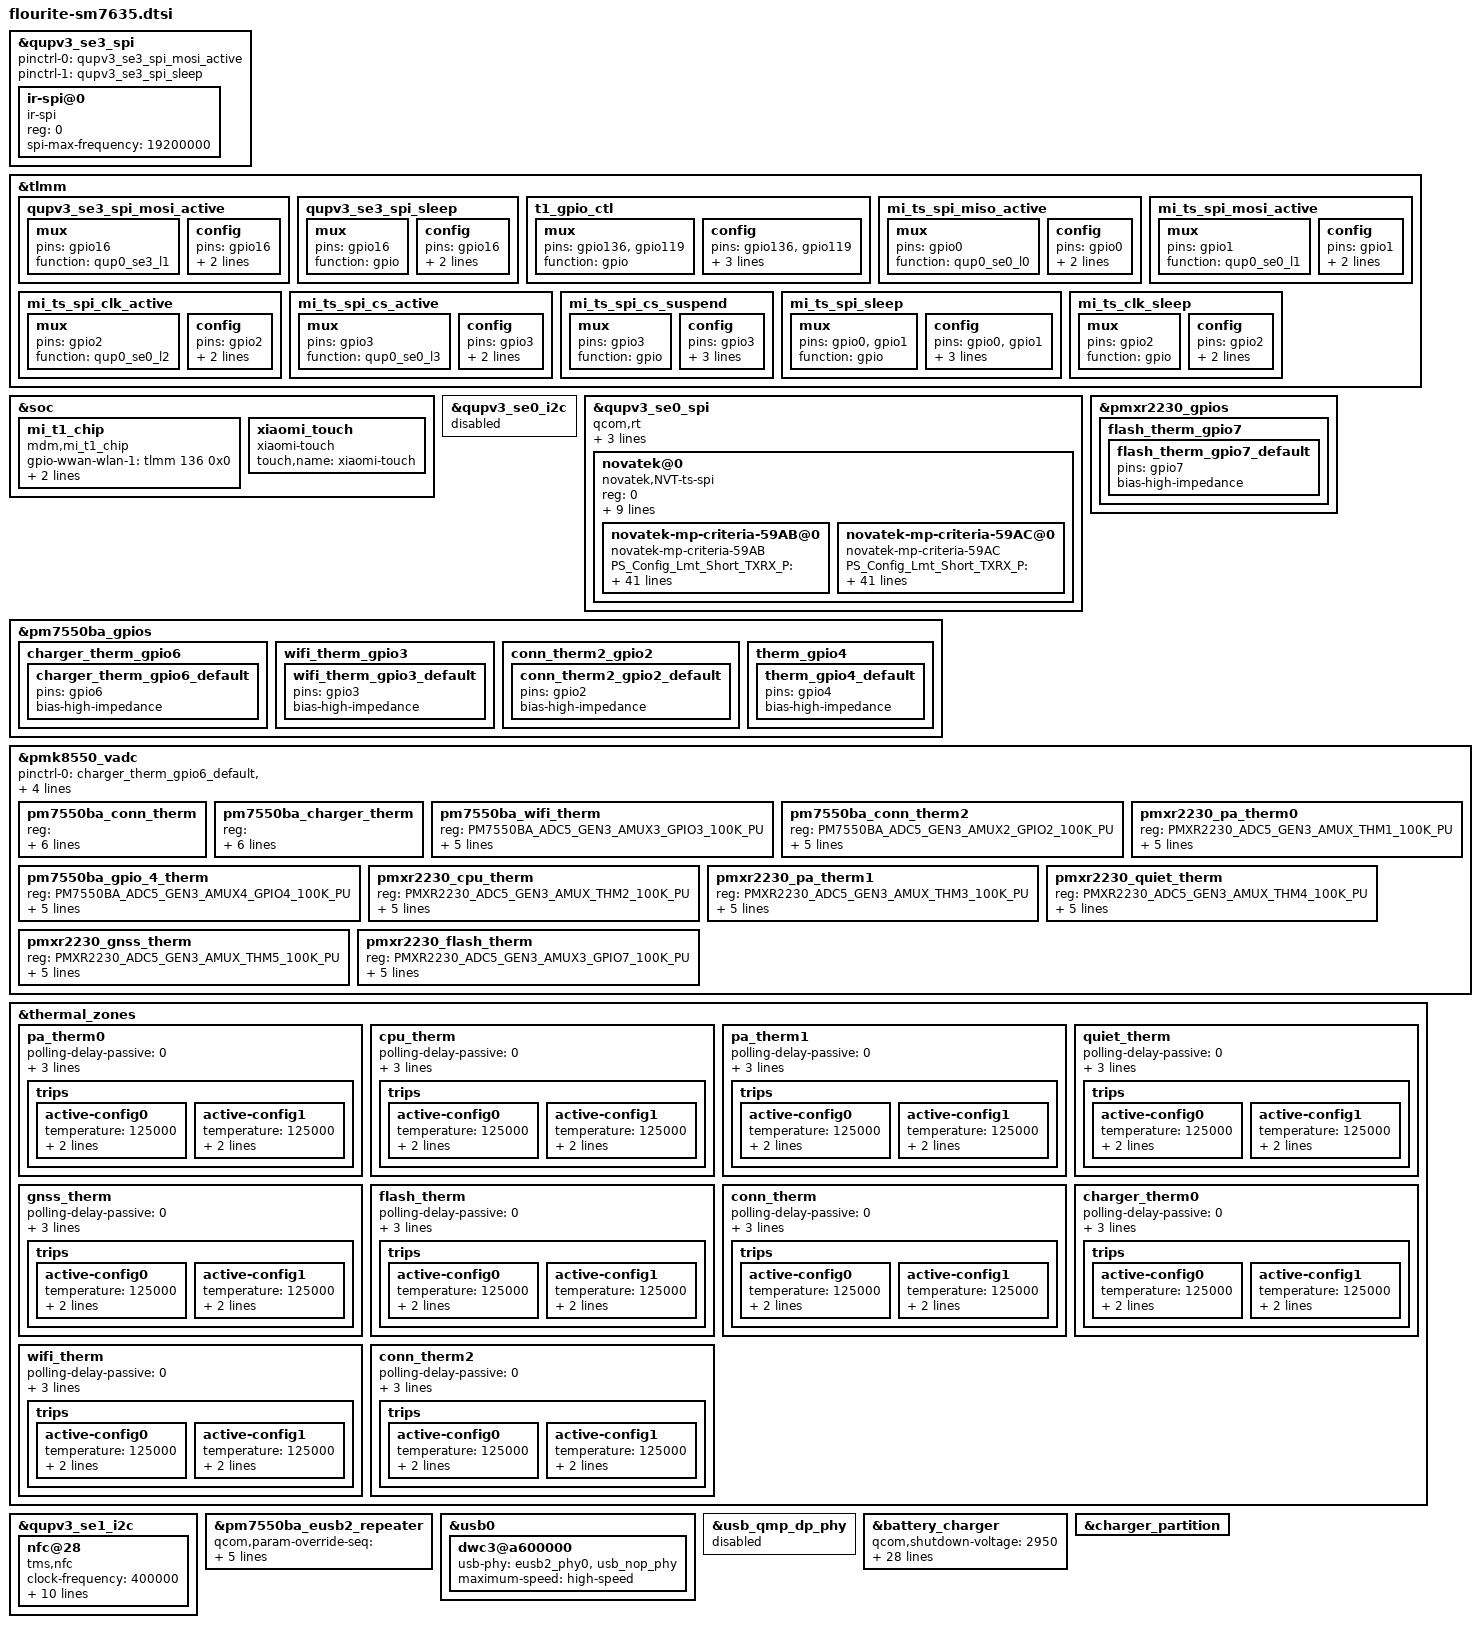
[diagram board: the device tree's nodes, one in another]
/*
  this file is for attribution only of flourite
  And public attribution of xiaomi platforms(like flourite and so and)
*/
#include "flourite-pinctrl.dtsi"
#include "xiaomi-sm7635-common.dtsi"
#include "volcano-pm7550ba.dtsi"
#include <dt-bindings/iio/qcom,spmi-adc5-gen3-pmxr2230.h>
#include "flourite-sm7635-xiaomi-fingerprint.dtsi"
#include "flourite-sm7635-xiaomi-hdbds.dtsi"

/* SENSOR start */
&qupv3_se3_spi {
	status = "ok";
	pinctrl-names = "default", "sleep";
	pinctrl-0 = <&qupv3_se3_spi_mosi_active>;
	pinctrl-1 = <&qupv3_se3_spi_sleep>;
	ir-spi@0 {
		compatible = "ir-spi";
		reg = <0>;
		spi-max-frequency = <19200000>;
		status = "ok";
	};
};

&tlmm {
	qupv3_se3_spi_mosi_active: qupv3_se3_spi_mosi_active {
		mux {
			pins = "gpio16";
			function = "qup0_se3_l1";
		};

		config {
			pins = "gpio16";
			drive-strength = <6>;
			bias-disable;
		};
	};

	qupv3_se3_spi_sleep: qupv3_se3_spi_sleep {
		mux {
			pins = "gpio16";
			function = "gpio";
		};

		config {
			pins = "gpio16";
			drive-strength = <2>;
			bias-disable;
		};
	};
};
/* SENSOR end */

/*modem start: t1 chip*/
&soc {
        mi_t1_chip {
                compatible = "mdm,mi_t1_chip";
                gpio-wwan-wlan-1 = <&tlmm 136 0x0>;
                gpio-wwan-wlan-2 = <&tlmm 119 0x0>;
                pinctrl-0       = <&t1_gpio_ctl>;
        };
};

&tlmm {
	t1_gpio_ctl: t1_gpio_ctl {
		mux {
			pins = "gpio136", "gpio119";
			function = "gpio";
		};
		config {
			pins = "gpio136", "gpio119";
			drive-strength = <2>;
			bias-disable;
			output-enable;
		};
	};
};
/*modem end: t1 chip*/


/*touch start*/
&soc {
	xiaomi_touch {
		compatible = "xiaomi-touch";
		status = "ok";
		touch,name = "xiaomi-touch";
	};
};

&qupv3_se0_i2c {
	status = "disable";
};

&tlmm {
	mi_ts_spi_miso_active: mi_ts_spi_miso_active {
		mux {
			pins = "gpio0";
			function = "qup0_se0_l0";
		};
		config {
			pins = "gpio0";
			drive-strength = <6>;
			bias-disable;
		};
	};
	mi_ts_spi_mosi_active: mi_ts_spi_mosi_active {
		mux {
			pins = "gpio1";
			function = "qup0_se0_l1";
		};
		config {
			pins = "gpio1";
			drive-strength = <6>;
			bias-disable;
		};
	};
	mi_ts_spi_clk_active: mi_ts_spi_clk_active {
		mux {
			pins = "gpio2";
			function = "qup0_se0_l2";
		};
		config {
			pins = "gpio2";
			drive-strength = <6>;
			bias-disable;
		};
	};
	mi_ts_spi_cs_active: mi_ts_spi_cs_active {
		mux {
			pins = "gpio3";
			function = "qup0_se0_l3";
		};
		config {
			pins = "gpio3";
			drive-strength = <6>;
			bias-disable;
		};
	};
	mi_ts_spi_cs_suspend: mi_ts_spi_cs_suspend {
		mux {
			pins = "gpio3";
			function = "gpio";
		};
		config {
			pins = "gpio3";
			drive-strength = <2>;
			bias-pull-down;
			output-low;
		};
	};
	mi_ts_spi_sleep: mi_ts_spi_sleep {
		mux {
			pins = "gpio0", "gpio1";
			function = "gpio";
		};
		config {
			pins = "gpio0", "gpio1";
			drive-strength = <2>;
			output-low;
			bias-disable;
		};
	};
	mi_ts_clk_sleep: mi_ts_clk_sleep {
		mux {
			pins = "gpio2";
			function = "gpio";
		};
		config {
			pins = "gpio2";
			drive-strength = <2>;
			bias-pull-down;
		};
	};
};

&qupv3_se0_spi {
	status = "ok";
	qcom,rt;
	pinctrl-0 = <&mi_ts_spi_mosi_active>, <&mi_ts_spi_miso_active>,
				<&mi_ts_spi_clk_active>;
	pinctrl-1 = <&mi_ts_spi_sleep>, <&mi_ts_clk_sleep>;
	//qcom,la-vm;
	/* Novatek device tree node */
	novatek@0 {
		compatible = "novatek,NVT-ts-spi";
		reg = <0>; //Same as CS ID
		status = "ok";
		spi-max-frequency = <19200000>;	//4800000,9600000,15000000,19200000

		novatek,irq-gpio = <&tlmm 70 0x2008>;
		novatek,lcd_id-gpio1 = <&tlmm 65 0x00>;
		novatek,lcd_id-gpio2 = <&tlmm 128 0x00>;
		spi-cs-setup-delay-ns = <300>;
		spi-cs-hold-delay-ns = <300>;
		pinctrl-0 = <&mi_ts_spi_cs_active>;
		pinctrl-1 = <&mi_ts_spi_cs_suspend>;
		pinctrl-names = "pmx_ts_active", "pmx_ts_suspend";

		/* MP */
		novatek,mp-support-dt;

		/* for Xiaomi flourite NT38771 CSOT6.83" panel module */
		novatek-mp-criteria-59AB@0 {
			#address-cells = <1>;
			#size-cells = <0>;
			compatible = "novatek-mp-criteria-59AB";

			/* MP Criteria */
			PS_Config_Lmt_Short_TXRX_P = <
				3500 3500 3500 3500 3500 3500 3500 3500 3500 3500 3500 3500 3500 3500 3500 3500 3500 3500
				3500 3500 3500 3500 3500 3500 3500 3500 3500 3500 3500 3500 3500 3500 3500 3500 3500 3500
				3500 3500 3500 3500 3500 3500 3500 3500 3500 3500 3500 3500 3500 3500 3500 3500 3500 3500
				3500 3500 3500 3500 3500 3500 3500 3500 3500 3500 3500 3500 3500 3500 3500 3500 3500 3500
				3500 3500 3500 3500 3500 3500 3500 3500 3500 3500 3500 3500 3500 3500 3500 3500 3500 3500
				3500 3500 3500 3500 3500 3500 3500 3500 3500 3500 3500 3500 3500 3500 3500 3500 3500 3500
				3500 3500 3500 3500 3500 3500 3500 3500 3500 3500 3500 3500 3500 3500 3500 3500 3500 3500
				3500 3500 3500 3500 3500 3500 3500 3500 3500 3500 3500 3500 3500 3500 3500 3500 3500 3500
				3500 3500 3500 3500 3500 3500 3500 3500 3500 3500 3500 3500 3500 3500 3500 3500 3500 3500
				3500 3500 3500 3500 3500 3500 3500 3500 3500 3500 3500 3500 3500 3500 3500 3500 3500 3500
				3500 3500 3500 3500 3500 3500 3500 3500 3500 3500 3500 3500 3500 3500 3500 3500 3500 3500
				3500 3500 3500 3500 3500 3500 3500 3500 3500 3500 3500 3500 3500 3500 3500 3500 3500 3500
				3500 3500 3500 3500 3500 3500 3500 3500 3500 3500 3500 3500 3500 3500 3500 3500 3500 3500
				3500 3500 3500 3500 3500 3500 3500 3500 3500 3500 3500 3500 3500 3500 3500 3500 3500 3500
				3500 3500 3500 3500 3500 3500 3500 3500 3500 3500 3500 3500 3500 3500 3500 3500 3500 3500
				3500 3500 3500 3500 3500 3500 3500 3500 3500 3500 3500 3500 3500 3500 3500 3500 3500 3500
				3500 3500 3500 3500 3500 3500 3500 3500 3500 3500 3500 3500 3500 3500 3500 3500 3500 3500
				3500 3500 3500 3500 3500 3500 3500 3500 3500 3500 3500 3500 3500 3500 3500 3500 3500 3500
				3500 3500 3500 3500 3500 3500 3500 3500 3500 3500 3500 3500 3500 3500 3500 3500 3500 3500
				3500 3500 3500 3500 3500 3500 3500 3500 3500 3500 3500 3500 3500 3500 3500 3500 3500 3500
				3500 3500 3500 3500 3500 3500 3500 3500 3500 3500 3500 3500 3500 3500 3500 3500 3500 3500
				3500 3500 3500 3500 3500 3500 3500 3500 3500 3500 3500 3500 3500 3500 3500 3500 3500 3500
				3500 3500 3500 3500 3500 3500 3500 3500 3500 3500 3500 3500 3500 3500 3500 3500 3500 3500
				3500 3500 3500 3500 3500 3500 3500 3500 3500 3500 3500 3500 3500 3500 3500 3500 3500 3500
				3500 3500 3500 3500 3500 3500 3500 3500 3500 3500 3500 3500 3500 3500 3500 3500 3500 3500
				3500 3500 3500 3500 3500 3500 3500 3500 3500 3500 3500 3500 3500 3500 3500 3500 3500 3500
				3500 3500 3500 3500 3500 3500 3500 3500 3500 3500 3500 3500 3500 3500 3500 3500 3500 3500
				3500 3500 3500 3500 3500 3500 3500 3500 3500 3500 3500 3500 3500 3500 3500 3500 3500 3500
				3500 3500 3500 3500 3500 3500 3500 3500 3500 3500 3500 3500 3500 3500 3500 3500 3500 3500
				3500 3500 3500 3500 3500 3500 3500 3500 3500 3500 3500 3500 3500 3500 3500 3500 3500 3500
				3500 3500 3500 3500 3500 3500 3500 3500 3500 3500 3500 3500 3500 3500 3500 3500 3500 3500
				3500 3500 3500 3500 3500 3500 3500 3500 3500 3500 3500 3500 3500 3500 3500 3500 3500 3500
				3500 3500 3500 3500 3500 3500 3500 3500 3500 3500 3500 3500 3500 3500 3500 3500 3500 3500
				3500 3500 3500 3500 3500 3500 3500 3500 3500 3500 3500 3500 3500 3500 3500 3500 3500 3500
				3500 3500 3500 3500 3500 3500 3500 3500 3500 3500 3500 3500 3500 3500 3500 3500 3500 3500
				3500 3500 3500 3500 3500 3500 3500 3500 3500 3500 3500 3500 3500 3500 3500 3500 3500 3500
				3500 3500 3500 3500 3500 3500 3500 3500 3500 3500 3500 3500 3500 3500 3500 3500 3500 3500
				3500 3500 3500 3500 3500 3500 3500 3500 3500 3500 3500 3500 3500 3500 3500 3500 3500 3500
				3500 3500 3500 3500 3500 3500 3500 3500 3500 3500 3500 3500 3500 3500 3500 3500 3500 3500
				>;

			PS_Config_Lmt_Short_TXRX_N = <
				1900 1900 1900 1900 1900 1900 1900 1900 1900 1900 1900 1900 1900 1900 1900 1900 1900 1900
				1900 1900 1900 1900 1900 1900 1900 1900 1900 1900 1900 1900 1900 1900 1900 1900 1900 1900
				1900 1900 1900 1900 1900 1900 1900 1900 1900 1900 1900 1900 1900 1900 1900 1900 1900 1900
				1900 1900 1900 1900 1900 1900 1900 1900 1900 1900 1900 1900 1900 1900 1900 1900 1900 1900
				1900 1900 1900 1900 1900 1900 1900 1900 1900 1900 1900 1900 1900 1900 1900 1900 1900 1900
				1900 1900 1900 1900 1900 1900 1900 1900 1900 1900 1900 1900 1900 1900 1900 1900 1900 1900
				1900 1900 1900 1900 1900 1900 1900 1900 1900 1900 1900 1900 1900 1900 1900 1900 1900 1900
				1900 1900 1900 1900 1900 1900 1900 1900 1900 1900 1900 1900 1900 1900 1900 1900 1900 1900
				1900 1900 1900 1900 1900 1900 1900 1900 1900 1900 1900 1900 1900 1900 1900 1900 1900 1900
				1900 1900 1900 1900 1900 1900 1900 1900 1900 1900 1900 1900 1900 1900 1900 1900 1900 1900
				1900 1900 1900 1900 1900 1900 1900 1900 1900 1900 1900 1900 1900 1900 1900 1900 1900 1900
				1900 1900 1900 1900 1900 1900 1900 1900 1900 1900 1900 1900 1900 1900 1900 1900 1900 1900
				1900 1900 1900 1900 1900 1900 1900 1900 1900 1900 1900 1900 1900 1900 1900 1900 1900 1900
				1900 1900 1900 1900 1900 1900 1900 1900 1900 1900 1900 1900 1900 1900 1900 1900 1900 1900
				1900 1900 1900 1900 1900 1900 1900 1900 1900 1900 1900 1900 1900 1900 1900 1900 1900 1900
				1900 1900 1900 1900 1900 1900 1900 1900 1900 1900 1900 1900 1900 1900 1900 1900 1900 1900
				1900 1900 1900 1900 1900 1900 1900 1900 1900 1900 1900 1900 1900 1900 1900 1900 1900 1900
				1900 1900 1900 1900 1900 1900 1900 1900 1900 1900 1900 1900 1900 1900 1900 1900 1900 1900
				1900 1900 1900 1900 1900 1900 1900 1900 1900 1900 1900 1900 1900 1900 1900 1900 1900 1900
				1900 1900 1900 1900 1900 1900 1900 1900 1900 1900 1900 1900 1900 1900 1900 1900 1900 1900
				1900 1900 1900 1900 1900 1900 1900 1900 1900 1900 1900 1900 1900 1900 1900 1900 1900 1900
				1900 1900 1900 1900 1900 1900 1900 1900 1900 1900 1900 1900 1900 1900 1900 1900 1900 1900
				1900 1900 1900 1900 1900 1900 1900 1900 1900 1900 1900 1900 1900 1900 1900 1900 1900 1900
				1900 1900 1900 1900 1900 1900 1900 1900 1900 1900 1900 1900 1900 1900 1900 1900 1900 1900
				1900 1900 1900 1900 1900 1900 1900 1900 1900 1900 1900 1900 1900 1900 1900 1900 1900 1900
				1900 1900 1900 1900 1900 1900 1900 1900 1900 1900 1900 1900 1900 1900 1900 1900 1900 1900
				1900 1900 1900 1900 1900 1900 1900 1900 1900 1900 1900 1900 1900 1900 1900 1900 1900 1900
				1900 1900 1900 1900 1900 1900 1900 1900 1900 1900 1900 1900 1900 1900 1900 1900 1900 1900
				1900 1900 1900 1900 1900 1900 1900 1900 1900 1900 1900 1900 1900 1900 1900 1900 1900 1900
				1900 1900 1900 1900 1900 1900 1900 1900 1900 1900 1900 1900 1900 1900 1900 1900 1900 1900
				1900 1900 1900 1900 1900 1900 1900 1900 1900 1900 1900 1900 1900 1900 1900 1900 1900 1900
				1900 1900 1900 1900 1900 1900 1900 1900 1900 1900 1900 1900 1900 1900 1900 1900 1900 1900
				1900 1900 1900 1900 1900 1900 1900 1900 1900 1900 1900 1900 1900 1900 1900 1900 1900 1900
				1900 1900 1900 1900 1900 1900 1900 1900 1900 1900 1900 1900 1900 1900 1900 1900 1900 1900
				1900 1900 1900 1900 1900 1900 1900 1900 1900 1900 1900 1900 1900 1900 1900 1900 1900 1900
				1900 1900 1900 1900 1900 1900 1900 1900 1900 1900 1900 1900 1900 1900 1900 1900 1900 1900
				1900 1900 1900 1900 1900 1900 1900 1900 1900 1900 1900 1900 1900 1900 1900 1900 1900 1900
				1900 1900 1900 1900 1900 1900 1900 1900 1900 1900 1900 1900 1900 1900 1900 1900 1900 1900
				1900 1900 1900 1900 1900 1900 1900 1900 1900 1900 1900 1900 1900 1900 1900 1900 1900 1900
				>;

			PS_Config_Lmt_Short_TXTX_P = <
				3500 3500 3500 3500 3500 3500 3500 3500 3500 3500 3500 3500 3500 3500 3500 3500 3500 3500
				>;

			PS_Config_Lmt_Short_TXTX_N = <
				1900 1900 1900 1900 1900 1900 1900 1900 1900 1900 1900 1900 1900 1900 1900 1900 1900 1900
				>;

			PS_Config_Lmt_Short_RXRX_P = <
				3500
				3500
				3500
				3500
				3500
				3500
				3500
				3500
				3500
				3500
				3500
				3500
				3500
				3500
				3500
				3500
				3500
				3500
				3500
				3500
				3500
				3500
				3500
				3500
				3500
				3500
				3500
				3500
				3500
				3500
				3500
				3500
				3500
				3500
				3500
				3500
				3500
				3500
				3500
				>;

			PS_Config_Lmt_Short_RXRX_N = <
				1900
				1900
				1900
				1900
				1900
				1900
				1900
				1900
				1900
				1900
				1900
				1900
				1900
				1900
				1900
				1900
				1900
				1900
				1900
				1900
				1900
				1900
				1900
				1900
				1900
				1900
				1900
				1900
				1900
				1900
				1900
				1900
				1900
				1900
				1900
				1900
				1900
				1900
				1900
				>;

			PS_Config_Lmt_Open_Mutual_P = <
				65535 5000 5000 5000 5000 5000 5000 5000 5000 5000 5000 5000 5000 5000 5000 5000 5000 65535
				5000 5000 5000 5000 5000 5000 5000 5000 5000 5000 5000 5000 5000 5000 5000 5000 5000 5000
				5000 5000 5000 5000 5000 5000 5000 5000 5000 5000 5000 5000 5000 5000 5000 5000 5000 5000
				5000 5000 5000 5000 5000 5000 5000 5000 5000 5000 5000 5000 5000 5000 5000 5000 5000 5000
				5000 5000 5000 5000 5000 5000 5000 5000 5000 5000 5000 5000 5000 5000 5000 5000 5000 5000
				5000 5000 5000 5000 5000 5000 5000 5000 5000 5000 5000 5000 5000 5000 5000 5000 5000 5000
				5000 5000 5000 5000 5000 5000 5000 5000 5000 5000 5000 5000 5000 5000 5000 5000 5000 5000
				5000 5000 5000 5000 5000 5000 5000 5000 5000 5000 5000 5000 5000 5000 5000 5000 5000 5000
				5000 5000 5000 5000 5000 5000 5000 5000 5000 5000 5000 5000 5000 5000 5000 5000 5000 5000
				5000 5000 5000 5000 5000 5000 5000 5000 5000 5000 5000 5000 5000 5000 5000 5000 5000 5000
				5000 5000 5000 5000 5000 5000 5000 5000 5000 5000 5000 5000 5000 5000 5000 5000 5000 5000
				5000 5000 5000 5000 5000 5000 5000 5000 5000 5000 5000 5000 5000 5000 5000 5000 5000 5000
				5000 5000 5000 5000 5000 5000 5000 5000 5000 5000 5000 5000 5000 5000 5000 5000 5000 5000
				5000 5000 5000 5000 5000 5000 5000 5000 5000 5000 5000 5000 5000 5000 5000 5000 5000 5000
				5000 5000 5000 5000 5000 5000 5000 5000 5000 5000 5000 5000 5000 5000 5000 5000 5000 5000
				5000 5000 5000 5000 5000 5000 5000 5000 5000 5000 5000 5000 5000 5000 5000 5000 5000 5000
				5000 5000 5000 5000 5000 5000 5000 5000 5000 5000 5000 5000 5000 5000 5000 5000 5000 5000
				5000 5000 5000 5000 5000 5000 5000 5000 5000 5000 5000 5000 5000 5000 5000 5000 5000 5000
				5000 5000 5000 5000 5000 5000 5000 5000 5000 5000 5000 5000 5000 5000 5000 5000 5000 5000
				5000 5000 5000 5000 5000 5000 5000 5000 5000 5000 5000 5000 5000 5000 5000 5000 5000 5000
				5000 5000 5000 5000 5000 5000 5000 5000 5000 5000 5000 5000 5000 5000 5000 5000 5000 5000
				5000 5000 5000 5000 5000 5000 5000 5000 5000 5000 5000 5000 5000 5000 5000 5000 5000 5000
				5000 5000 5000 5000 5000 5000 5000 5000 5000 5000 5000 5000 5000 5000 5000 5000 5000 5000
				5000 5000 5000 5000 5000 5000 5000 5000 5000 5000 5000 5000 5000 5000 5000 5000 5000 5000
				5000 5000 5000 5000 5000 5000 5000 5000 5000 5000 5000 5000 5000 5000 5000 5000 5000 5000
				5000 5000 5000 5000 5000 5000 5000 5000 5000 5000 5000 5000 5000 5000 5000 5000 5000 5000
				5000 5000 5000 5000 5000 5000 5000 5000 5000 5000 5000 5000 5000 5000 5000 5000 5000 5000
				5000 5000 5000 5000 5000 5000 5000 5000 5000 5000 5000 5000 5000 5000 5000 5000 5000 5000
				5000 5000 5000 5000 5000 5000 5000 5000 5000 5000 5000 5000 5000 5000 5000 5000 5000 5000
				5000 5000 5000 5000 5000 5000 5000 5000 5000 5000 5000 5000 5000 5000 5000 5000 5000 5000
				5000 5000 5000 5000 5000 5000 5000 5000 5000 5000 5000 5000 5000 5000 5000 5000 5000 5000
				5000 5000 5000 5000 5000 5000 5000 5000 5000 5000 5000 5000 5000 5000 5000 5000 5000 5000
				5000 5000 5000 5000 5000 5000 5000 5000 5000 5000 5000 5000 5000 5000 5000 5000 5000 5000
				5000 5000 5000 5000 5000 5000 5000 5000 5000 5000 5000 5000 5000 5000 5000 5000 5000 5000
				5000 5000 5000 5000 5000 5000 5000 5000 5000 5000 5000 5000 5000 5000 5000 5000 5000 5000
				5000 5000 5000 5000 5000 5000 5000 5000 5000 5000 5000 5000 5000 5000 5000 5000 5000 5000
				5000 5000 5000 5000 5000 5000 5000 5000 5000 5000 5000 5000 5000 5000 5000 5000 5000 5000
				5000 5000 5000 5000 5000 5000 5000 5000 5000 5000 5000 5000 5000 5000 5000 5000 5000 5000
				65535 5000 5000 5000 5000 5000 5000 5000 5000 5000 5000 5000 5000 5000 5000 5000 5000 65535
				>;

			PS_Config_Lmt_Open_Mutual_N = <
				(-65535) 100 100 100 100 100 100 100 100 100 100 100 100 100 100 100 100 (-65535)
				100 100 100 100 100 100 100 100 100 100 100 100 100 100 100 100 100 100
				100 100 100 100 100 100 100 100 100 100 100 100 100 100 100 100 100 100
				100 100 100 100 100 100 100 100 100 100 100 100 100 100 100 100 100 100
				100 100 100 100 100 100 100 100 100 100 100 100 100 100 100 100 100 100
				100 100 100 100 100 100 100 100 100 100 100 100 100 100 100 100 100 100
				100 100 100 100 100 100 100 100 100 100 100 100 100 100 100 100 100 100
				100 100 100 100 100 100 100 100 100 100 100 100 100 100 100 100 100 100
				100 100 100 100 100 100 100 100 100 100 100 100 100 100 100 100 100 100
				100 100 100 100 100 100 100 100 100 100 100 100 100 100 100 100 100 100
				100 100 100 100 100 100 100 100 100 100 100 100 100 100 100 100 100 100
				100 100 100 100 100 100 100 100 100 100 100 100 100 100 100 100 100 100
				100 100 100 100 100 100 100 100 100 100 100 100 100 100 100 100 100 100
				100 100 100 100 100 100 100 100 100 100 100 100 100 100 100 100 100 100
				100 100 100 100 100 100 100 100 100 100 100 100 100 100 100 100 100 100
				100 100 100 100 100 100 100 100 100 100 100 100 100 100 100 100 100 100
				100 100 100 100 100 100 100 100 100 100 100 100 100 100 100 100 100 100
				100 100 100 100 100 100 100 100 100 100 100 100 100 100 100 100 100 100
				100 100 100 100 100 100 100 100 100 100 100 100 100 100 100 100 100 100
				100 100 100 100 100 100 100 100 100 100 100 100 100 100 100 100 100 100
				100 100 100 100 100 100 100 100 100 100 100 100 100 100 100 100 100 100
				100 100 100 100 100 100 100 100 100 100 100 100 100 100 100 100 100 100
				100 100 100 100 100 100 100 100 100 100 100 100 100 100 100 100 100 100
				100 100 100 100 100 100 100 100 100 100 100 100 100 100 100 100 100 100
				100 100 100 100 100 100 100 100 100 100 100 100 100 100 100 100 100 100
				100 100 100 100 100 100 100 100 100 100 100 100 100 100 100 100 100 100
				100 100 100 100 100 100 100 100 100 100 100 100 100 100 100 100 100 100
				100 100 100 100 100 100 100 100 100 100 100 100 100 100 100 100 100 100
				100 100 100 100 100 100 100 100 100 100 100 100 100 100 100 100 100 100
				100 100 100 100 100 100 100 100 100 100 100 100 100 100 100 100 100 100
				100 100 100 100 100 100 100 100 100 100 100 100 100 100 100 100 100 100
				100 100 100 100 100 100 100 100 100 100 100 100 100 100 100 100 100 100
				100 100 100 100 100 100 100 100 100 100 100 100 100 100 100 100 100 100
				100 100 100 100 100 100 100 100 100 100 100 100 100 100 100 100 100 100
				100 100 100 100 100 100 100 100 100 100 100 100 100 100 100 100 100 100
				100 100 100 100 100 100 100 100 100 100 100 100 100 100 100 100 100 100
				100 100 100 100 100 100 100 100 100 100 100 100 100 100 100 100 100 100
				100 100 100 100 100 100 100 100 100 100 100 100 100 100 100 100 100 100
				(-65535) 100 100 100 100 100 100 100 100 100 100 100 100 100 100 100 100 (-65535)
				>;

			PS_Config_Lmt_Open_SelfTX_P = <
				5000 5000 5000 5000 5000 5000 5000 5000 5000 5000 5000 5000 5000 5000 5000 5000 5000 5000
				>;

			PS_Config_Lmt_Open_SelfTX_N = <
				100 100 100 100 100 100 100 100 100 100 100 100 100 100 100 100 100 100
				>;

			PS_Config_Lmt_Open_SelfRX_P = <
				5000
				5000
				5000
				5000
				5000
				5000
				5000
				5000
				5000
				5000
				5000
				5000
				5000
				5000
				5000
				5000
				5000
				5000
				5000
				5000
				5000
				5000
				5000
				5000
				5000
				5000
				5000
				5000
				5000
				5000
				5000
				5000
				5000
				5000
				5000
				5000
				5000
				5000
				5000
				>;

			PS_Config_Lmt_Open_SelfRX_N = <
				100
				100
				100
				100
				100
				100
				100
				100
				100
				100
				100
				100
				100
				100
				100
				100
				100
				100
				100
				100
				100
				100
				100
				100
				100
				100
				100
				100
				100
				100
				100
				100
				100
				100
				100
				100
				100
				100
				100
				>;

			PS_Config_Lmt_FW_Rawdata_P = <
				5000 5000 5000 5000 5000 5000 5000 5000 5000 5000 5000 5000 5000 5000 5000 5000 5000 5000
				5000 5000 5000 5000 5000 5000 5000 5000 5000 5000 5000 5000 5000 5000 5000 5000 5000 5000
				5000 5000 5000 5000 5000 5000 5000 5000 5000 5000 5000 5000 5000 5000 5000 5000 5000 5000
				5000 5000 5000 5000 5000 5000 5000 5000 5000 5000 5000 5000 5000 5000 5000 5000 5000 5000
				5000 5000 5000 5000 5000 5000 5000 5000 5000 5000 5000 5000 5000 5000 5000 5000 5000 5000
				5000 5000 5000 5000 5000 5000 5000 5000 5000 5000 5000 5000 5000 5000 5000 5000 5000 5000
				5000 5000 5000 5000 5000 5000 5000 5000 5000 5000 5000 5000 5000 5000 5000 5000 5000 5000
				5000 5000 5000 5000 5000 5000 5000 5000 5000 5000 5000 5000 5000 5000 5000 5000 5000 5000
				5000 5000 5000 5000 5000 5000 5000 5000 5000 5000 5000 5000 5000 5000 5000 5000 5000 5000
				5000 5000 5000 5000 5000 5000 5000 5000 5000 5000 5000 5000 5000 5000 5000 5000 5000 5000
				5000 5000 5000 5000 5000 5000 5000 5000 5000 5000 5000 5000 5000 5000 5000 5000 5000 5000
				5000 5000 5000 5000 5000 5000 5000 5000 5000 5000 5000 5000 5000 5000 5000 5000 5000 5000
				5000 5000 5000 5000 5000 5000 5000 5000 5000 5000 5000 5000 5000 5000 5000 5000 5000 5000
				5000 5000 5000 5000 5000 5000 5000 5000 5000 5000 5000 5000 5000 5000 5000 5000 5000 5000
				5000 5000 5000 5000 5000 5000 5000 5000 5000 5000 5000 5000 5000 5000 5000 5000 5000 5000
				5000 5000 5000 5000 5000 5000 5000 5000 5000 5000 5000 5000 5000 5000 5000 5000 5000 5000
				5000 5000 5000 5000 5000 5000 5000 5000 5000 5000 5000 5000 5000 5000 5000 5000 5000 5000
				5000 5000 5000 5000 5000 5000 5000 5000 5000 5000 5000 5000 5000 5000 5000 5000 5000 5000
				5000 5000 5000 5000 5000 5000 5000 5000 5000 5000 5000 5000 5000 5000 5000 5000 5000 5000
				5000 5000 5000 5000 5000 5000 5000 5000 5000 5000 5000 5000 5000 5000 5000 5000 5000 5000
				5000 5000 5000 5000 5000 5000 5000 5000 5000 5000 5000 5000 5000 5000 5000 5000 5000 5000
				5000 5000 5000 5000 5000 5000 5000 5000 5000 5000 5000 5000 5000 5000 5000 5000 5000 5000
				5000 5000 5000 5000 5000 5000 5000 5000 5000 5000 5000 5000 5000 5000 5000 5000 5000 5000
				5000 5000 5000 5000 5000 5000 5000 5000 5000 5000 5000 5000 5000 5000 5000 5000 5000 5000
				5000 5000 5000 5000 5000 5000 5000 5000 5000 5000 5000 5000 5000 5000 5000 5000 5000 5000
				5000 5000 5000 5000 5000 5000 5000 5000 5000 5000 5000 5000 5000 5000 5000 5000 5000 5000
				5000 5000 5000 5000 5000 5000 5000 5000 5000 5000 5000 5000 5000 5000 5000 5000 5000 5000
				5000 5000 5000 5000 5000 5000 5000 5000 5000 5000 5000 5000 5000 5000 5000 5000 5000 5000
				5000 5000 5000 5000 5000 5000 5000 5000 5000 5000 5000 5000 5000 5000 5000 5000 5000 5000
				5000 5000 5000 5000 5000 5000 5000 5000 5000 5000 5000 5000 5000 5000 5000 5000 5000 5000
				5000 5000 5000 5000 5000 5000 5000 5000 5000 5000 5000 5000 5000 5000 5000 5000 5000 5000
				5000 5000 5000 5000 5000 5000 5000 5000 5000 5000 5000 5000 5000 5000 5000 5000 5000 5000
				5000 5000 5000 5000 5000 5000 5000 5000 5000 5000 5000 5000 5000 5000 5000 5000 5000 5000
				5000 5000 5000 5000 5000 5000 5000 5000 5000 5000 5000 5000 5000 5000 5000 5000 5000 5000
				5000 5000 5000 5000 5000 5000 5000 5000 5000 5000 5000 5000 5000 5000 5000 5000 5000 5000
				5000 5000 5000 5000 5000 5000 5000 5000 5000 5000 5000 5000 5000 5000 5000 5000 5000 5000
				5000 5000 5000 5000 5000 5000 5000 5000 5000 5000 5000 5000 5000 5000 5000 5000 5000 5000
				5000 5000 5000 5000 5000 5000 5000 5000 5000 5000 5000 5000 5000 5000 5000 5000 5000 5000
				5000 5000 5000 5000 5000 5000 5000 5000 5000 5000 5000 5000 5000 5000 5000 5000 5000 5000
				>;

			PS_Config_Lmt_FW_Rawdata_N = <
				1000 1000 1000 1000 1000 1000 1000 1000 1000 1000 1000 1000 1000 1000 1000 1000 1000 1000
				1000 1000 1000 1000 1000 1000 1000 1000 1000 1000 1000 1000 1000 1000 1000 1000 1000 1000
				1000 1000 1000 1000 1000 1000 1000 1000 1000 1000 1000 1000 1000 1000 1000 1000 1000 1000
				1000 1000 1000 1000 1000 1000 1000 1000 1000 1000 1000 1000 1000 1000 1000 1000 1000 1000
				1000 1000 1000 1000 1000 1000 1000 1000 1000 1000 1000 1000 1000 1000 1000 1000 1000 1000
				1000 1000 1000 1000 1000 1000 1000 1000 1000 1000 1000 1000 1000 1000 1000 1000 1000 1000
				1000 1000 1000 1000 1000 1000 1000 1000 1000 1000 1000 1000 1000 1000 1000 1000 1000 1000
				1000 1000 1000 1000 1000 1000 1000 1000 1000 1000 1000 1000 1000 1000 1000 1000 1000 1000
				1000 1000 1000 1000 1000 1000 1000 1000 1000 1000 1000 1000 1000 1000 1000 1000 1000 1000
				1000 1000 1000 1000 1000 1000 1000 1000 1000 1000 1000 1000 1000 1000 1000 1000 1000 1000
				1000 1000 1000 1000 1000 1000 1000 1000 1000 1000 1000 1000 1000 1000 1000 1000 1000 1000
				1000 1000 1000 1000 1000 1000 1000 1000 1000 1000 1000 1000 1000 1000 1000 1000 1000 1000
				1000 1000 1000 1000 1000 1000 1000 1000 1000 1000 1000 1000 1000 1000 1000 1000 1000 1000
				1000 1000 1000 1000 1000 1000 1000 1000 1000 1000 1000 1000 1000 1000 1000 1000 1000 1000
				1000 1000 1000 1000 1000 1000 1000 1000 1000 1000 1000 1000 1000 1000 1000 1000 1000 1000
				1000 1000 1000 1000 1000 1000 1000 1000 1000 1000 1000 1000 1000 1000 1000 1000 1000 1000
				1000 1000 1000 1000 1000 1000 1000 1000 1000 1000 1000 1000 1000 1000 1000 1000 1000 1000
				1000 1000 1000 1000 1000 1000 1000 1000 1000 1000 1000 1000 1000 1000 1000 1000 1000 1000
				1000 1000 1000 1000 1000 1000 1000 1000 1000 1000 1000 1000 1000 1000 1000 1000 1000 1000
				1000 1000 1000 1000 1000 1000 1000 1000 1000 1000 1000 1000 1000 1000 1000 1000 1000 1000
				1000 1000 1000 1000 1000 1000 1000 1000 1000 1000 1000 1000 1000 1000 1000 1000 1000 1000
				1000 1000 1000 1000 1000 1000 1000 1000 1000 1000 1000 1000 1000 1000 1000 1000 1000 1000
				1000 1000 1000 1000 1000 1000 1000 1000 1000 1000 1000 1000 1000 1000 1000 1000 1000 1000
				1000 1000 1000 1000 1000 1000 1000 1000 1000 1000 1000 1000 1000 1000 1000 1000 1000 1000
				1000 1000 1000 1000 1000 1000 1000 1000 1000 1000 1000 1000 1000 1000 1000 1000 1000 1000
				1000 1000 1000 1000 1000 1000 1000 1000 1000 1000 1000 1000 1000 1000 1000 1000 1000 1000
				1000 1000 1000 1000 1000 1000 1000 1000 1000 1000 1000 1000 1000 1000 1000 1000 1000 1000
				1000 1000 1000 1000 1000 1000 1000 1000 1000 1000 1000 1000 1000 1000 1000 1000 1000 1000
				1000 1000 1000 1000 1000 1000 1000 1000 1000 1000 1000 1000 1000 1000 1000 1000 1000 1000
				1000 1000 1000 1000 1000 1000 1000 1000 1000 1000 1000 1000 1000 1000 1000 1000 1000 1000
				1000 1000 1000 1000 1000 1000 1000 1000 1000 1000 1000 1000 1000 1000 1000 1000 1000 1000
				1000 1000 1000 1000 1000 1000 1000 1000 1000 1000 1000 1000 1000 1000 1000 1000 1000 1000
				1000 1000 1000 1000 1000 1000 1000 1000 1000 1000 1000 1000 1000 1000 1000 1000 1000 1000
				1000 1000 1000 1000 1000 1000 1000 1000 1000 1000 1000 1000 1000 1000 1000 1000 1000 1000
				1000 1000 1000 1000 1000 1000 1000 1000 1000 1000 1000 1000 1000 1000 1000 1000 1000 1000
				1000 1000 1000 1000 1000 1000 1000 1000 1000 1000 1000 1000 1000 1000 1000 1000 1000 1000
				1000 1000 1000 1000 1000 1000 1000 1000 1000 1000 1000 1000 1000 1000 1000 1000 1000 1000
				1000 1000 1000 1000 1000 1000 1000 1000 1000 1000 1000 1000 1000 1000 1000 1000 1000 1000
				1000 1000 1000 1000 1000 1000 1000 1000 1000 1000 1000 1000 1000 1000 1000 1000 1000 1000
				>;

			PS_Config_Lmt_FW_CC_P = <
				80 80 80 80 80 80 80 80 80 80 80 80 80 80 80 80 80 80
				80 80 80 80 80 80 80 80 80 80 80 80 80 80 80 80 80 80
				80 80 80 80 80 80 80 80 80 80 80 80 80 80 80 80 80 80
				80 80 80 80 80 80 80 80 80 80 80 80 80 80 80 80 80 80
				80 80 80 80 80 80 80 80 80 80 80 80 80 80 80 80 80 80
				80 80 80 80 80 80 80 80 80 80 80 80 80 80 80 80 80 80
				80 80 80 80 80 80 80 80 80 80 80 80 80 80 80 80 80 80
				80 80 80 80 80 80 80 80 80 80 80 80 80 80 80 80 80 80
				80 80 80 80 80 80 80 80 80 80 80 80 80 80 80 80 80 80
				80 80 80 80 80 80 80 80 80 80 80 80 80 80 80 80 80 80
				80 80 80 80 80 80 80 80 80 80 80 80 80 80 80 80 80 80
				80 80 80 80 80 80 80 80 80 80 80 80 80 80 80 80 80 80
				80 80 80 80 80 80 80 80 80 80 80 80 80 80 80 80 80 80
				80 80 80 80 80 80 80 80 80 80 80 80 80 80 80 80 80 80
				80 80 80 80 80 80 80 80 80 80 80 80 80 80 80 80 80 80
				80 80 80 80 80 80 80 80 80 80 80 80 80 80 80 80 80 80
				80 80 80 80 80 80 80 80 80 80 80 80 80 80 80 80 80 80
				80 80 80 80 80 80 80 80 80 80 80 80 80 80 80 80 80 80
				80 80 80 80 80 80 80 80 80 80 80 80 80 80 80 80 80 80
				80 80 80 80 80 80 80 80 80 80 80 80 80 80 80 80 80 80
				80 80 80 80 80 80 80 80 80 80 80 80 80 80 80 80 80 80
				80 80 80 80 80 80 80 80 80 80 80 80 80 80 80 80 80 80
				80 80 80 80 80 80 80 80 80 80 80 80 80 80 80 80 80 80
				80 80 80 80 80 80 80 80 80 80 80 80 80 80 80 80 80 80
				80 80 80 80 80 80 80 80 80 80 80 80 80 80 80 80 80 80
				80 80 80 80 80 80 80 80 80 80 80 80 80 80 80 80 80 80
				80 80 80 80 80 80 80 80 80 80 80 80 80 80 80 80 80 80
				80 80 80 80 80 80 80 80 80 80 80 80 80 80 80 80 80 80
				80 80 80 80 80 80 80 80 80 80 80 80 80 80 80 80 80 80
				80 80 80 80 80 80 80 80 80 80 80 80 80 80 80 80 80 80
				80 80 80 80 80 80 80 80 80 80 80 80 80 80 80 80 80 80
				80 80 80 80 80 80 80 80 80 80 80 80 80 80 80 80 80 80
				80 80 80 80 80 80 80 80 80 80 80 80 80 80 80 80 80 80
				80 80 80 80 80 80 80 80 80 80 80 80 80 80 80 80 80 80
				80 80 80 80 80 80 80 80 80 80 80 80 80 80 80 80 80 80
				80 80 80 80 80 80 80 80 80 80 80 80 80 80 80 80 80 80
				80 80 80 80 80 80 80 80 80 80 80 80 80 80 80 80 80 80
				80 80 80 80 80 80 80 80 80 80 80 80 80 80 80 80 80 80
				80 80 80 80 80 80 80 80 80 80 80 80 80 80 80 80 80 80
				>;

			PS_Config_Lmt_FW_CC_N = <
				(-80) (-80) (-80) (-80) (-80) (-80) (-80) (-80) (-80) (-80) (-80) (-80) (-80) (-80) (-80) (-80) (-80) (-80)
				(-80) (-80) (-80) (-80) (-80) (-80) (-80) (-80) (-80) (-80) (-80) (-80) (-80) (-80) (-80) (-80) (-80) (-80)
				(-80) (-80) (-80) (-80) (-80) (-80) (-80) (-80) (-80) (-80) (-80) (-80) (-80) (-80) (-80) (-80) (-80) (-80)
				(-80) (-80) (-80) (-80) (-80) (-80) (-80) (-80) (-80) (-80) (-80) (-80) (-80) (-80) (-80) (-80) (-80) (-80)
				(-80) (-80) (-80) (-80) (-80) (-80) (-80) (-80) (-80) (-80) (-80) (-80) (-80) (-80) (-80) (-80) (-80) (-80)
				(-80) (-80) (-80) (-80) (-80) (-80) (-80) (-80) (-80) (-80) (-80) (-80) (-80) (-80) (-80) (-80) (-80) (-80)
				(-80) (-80) (-80) (-80) (-80) (-80) (-80) (-80) (-80) (-80) (-80) (-80) (-80) (-80) (-80) (-80) (-80) (-80)
				(-80) (-80) (-80) (-80) (-80) (-80) (-80) (-80) (-80) (-80) (-80) (-80) (-80) (-80) (-80) (-80) (-80) (-80)
				(-80) (-80) (-80) (-80) (-80) (-80) (-80) (-80) (-80) (-80) (-80) (-80) (-80) (-80) (-80) (-80) (-80) (-80)
				(-80) (-80) (-80) (-80) (-80) (-80) (-80) (-80) (-80) (-80) (-80) (-80) (-80) (-80) (-80) (-80) (-80) (-80)
				(-80) (-80) (-80) (-80) (-80) (-80) (-80) (-80) (-80) (-80) (-80) (-80) (-80) (-80) (-80) (-80) (-80) (-80)
				(-80) (-80) (-80) (-80) (-80) (-80) (-80) (-80) (-80) (-80) (-80) (-80) (-80) (-80) (-80) (-80) (-80) (-80)
				(-80) (-80) (-80) (-80) (-80) (-80) (-80) (-80) (-80) (-80) (-80) (-80) (-80) (-80) (-80) (-80) (-80) (-80)
				(-80) (-80) (-80) (-80) (-80) (-80) (-80) (-80) (-80) (-80) (-80) (-80) (-80) (-80) (-80) (-80) (-80) (-80)
				(-80) (-80) (-80) (-80) (-80) (-80) (-80) (-80) (-80) (-80) (-80) (-80) (-80) (-80) (-80) (-80) (-80) (-80)
				(-80) (-80) (-80) (-80) (-80) (-80) (-80) (-80) (-80) (-80) (-80) (-80) (-80) (-80) (-80) (-80) (-80) (-80)
				(-80) (-80) (-80) (-80) (-80) (-80) (-80) (-80) (-80) (-80) (-80) (-80) (-80) (-80) (-80) (-80) (-80) (-80)
				(-80) (-80) (-80) (-80) (-80) (-80) (-80) (-80) (-80) (-80) (-80) (-80) (-80) (-80) (-80) (-80) (-80) (-80)
				(-80) (-80) (-80) (-80) (-80) (-80) (-80) (-80) (-80) (-80) (-80) (-80) (-80) (-80) (-80) (-80) (-80) (-80)
				(-80) (-80) (-80) (-80) (-80) (-80) (-80) (-80) (-80) (-80) (-80) (-80) (-80) (-80) (-80) (-80) (-80) (-80)
				(-80) (-80) (-80) (-80) (-80) (-80) (-80) (-80) (-80) (-80) (-80) (-80) (-80) (-80) (-80) (-80) (-80) (-80)
				(-80) (-80) (-80) (-80) (-80) (-80) (-80) (-80) (-80) (-80) (-80) (-80) (-80) (-80) (-80) (-80) (-80) (-80)
				(-80) (-80) (-80) (-80) (-80) (-80) (-80) (-80) (-80) (-80) (-80) (-80) (-80) (-80) (-80) (-80) (-80) (-80)
				(-80) (-80) (-80) (-80) (-80) (-80) (-80) (-80) (-80) (-80) (-80) (-80) (-80) (-80) (-80) (-80) (-80) (-80)
				(-80) (-80) (-80) (-80) (-80) (-80) (-80) (-80) (-80) (-80) (-80) (-80) (-80) (-80) (-80) (-80) (-80) (-80)
				(-80) (-80) (-80) (-80) (-80) (-80) (-80) (-80) (-80) (-80) (-80) (-80) (-80) (-80) (-80) (-80) (-80) (-80)
				(-80) (-80) (-80) (-80) (-80) (-80) (-80) (-80) (-80) (-80) (-80) (-80) (-80) (-80) (-80) (-80) (-80) (-80)
				(-80) (-80) (-80) (-80) (-80) (-80) (-80) (-80) (-80) (-80) (-80) (-80) (-80) (-80) (-80) (-80) (-80) (-80)
				(-80) (-80) (-80) (-80) (-80) (-80) (-80) (-80) (-80) (-80) (-80) (-80) (-80) (-80) (-80) (-80) (-80) (-80)
				(-80) (-80) (-80) (-80) (-80) (-80) (-80) (-80) (-80) (-80) (-80) (-80) (-80) (-80) (-80) (-80) (-80) (-80)
				(-80) (-80) (-80) (-80) (-80) (-80) (-80) (-80) (-80) (-80) (-80) (-80) (-80) (-80) (-80) (-80) (-80) (-80)
				(-80) (-80) (-80) (-80) (-80) (-80) (-80) (-80) (-80) (-80) (-80) (-80) (-80) (-80) (-80) (-80) (-80) (-80)
				(-80) (-80) (-80) (-80) (-80) (-80) (-80) (-80) (-80) (-80) (-80) (-80) (-80) (-80) (-80) (-80) (-80) (-80)
				(-80) (-80) (-80) (-80) (-80) (-80) (-80) (-80) (-80) (-80) (-80) (-80) (-80) (-80) (-80) (-80) (-80) (-80)
				(-80) (-80) (-80) (-80) (-80) (-80) (-80) (-80) (-80) (-80) (-80) (-80) (-80) (-80) (-80) (-80) (-80) (-80)
				(-80) (-80) (-80) (-80) (-80) (-80) (-80) (-80) (-80) (-80) (-80) (-80) (-80) (-80) (-80) (-80) (-80) (-80)
				(-80) (-80) (-80) (-80) (-80) (-80) (-80) (-80) (-80) (-80) (-80) (-80) (-80) (-80) (-80) (-80) (-80) (-80)
				(-80) (-80) (-80) (-80) (-80) (-80) (-80) (-80) (-80) (-80) (-80) (-80) (-80) (-80) (-80) (-80) (-80) (-80)
				(-80) (-80) (-80) (-80) (-80) (-80) (-80) (-80) (-80) (-80) (-80) (-80) (-80) (-80) (-80) (-80) (-80) (-80)
				>;

			PS_Config_Lmt_FW_Diff_P = <
				75 75 75 75 75 75 75 75 75 75 75 75 75 75 75 75 75 75
				75 75 75 75 75 75 75 75 75 75 75 75 75 75 75 75 75 75
				75 75 75 75 75 75 75 75 75 75 75 75 75 75 75 75 75 75
				75 75 75 75 75 75 75 75 75 75 75 75 75 75 75 75 75 75
				75 75 75 75 75 75 75 75 75 75 75 75 75 75 75 75 75 75
				75 75 75 75 75 75 75 75 75 75 75 75 75 75 75 75 75 75
				75 75 75 75 75 75 75 75 75 75 75 75 75 75 75 75 75 75
				75 75 75 75 75 75 75 75 75 75 75 75 75 75 75 75 75 75
				75 75 75 75 75 75 75 75 75 75 75 75 75 75 75 75 75 75
				75 75 75 75 75 75 75 75 75 75 75 75 75 75 75 75 75 75
				75 75 75 75 75 75 75 75 75 75 75 75 75 75 75 75 75 75
				75 75 75 75 75 75 75 75 75 75 75 75 75 75 75 75 75 75
				75 75 75 75 75 75 75 75 75 75 75 75 75 75 75 75 75 75
				75 75 75 75 75 75 75 75 75 75 75 75 75 75 75 75 75 75
				75 75 75 75 75 75 75 75 75 75 75 75 75 75 75 75 75 75
				75 75 75 75 75 75 75 75 75 75 75 75 75 75 75 75 75 75
				75 75 75 75 75 75 75 75 75 75 75 75 75 75 75 75 75 75
				75 75 75 75 75 75 75 75 75 75 75 75 75 75 75 75 75 75
				75 75 75 75 75 75 75 75 75 75 75 75 75 75 75 75 75 75
				75 75 75 75 75 75 75 75 75 75 75 75 75 75 75 75 75 75
				75 75 75 75 75 75 75 75 75 75 75 75 75 75 75 75 75 75
				75 75 75 75 75 75 75 75 75 75 75 75 75 75 75 75 75 75
				75 75 75 75 75 75 75 75 75 75 75 75 75 75 75 75 75 75
				75 75 75 75 75 75 75 75 75 75 75 75 75 75 75 75 75 75
				75 75 75 75 75 75 75 75 75 75 75 75 75 75 75 75 75 75
				75 75 75 75 75 75 75 75 75 75 75 75 75 75 75 75 75 75
				75 75 75 75 75 75 75 75 75 75 75 75 75 75 75 75 75 75
				75 75 75 75 75 75 75 75 75 75 75 75 75 75 75 75 75 75
				75 75 75 75 75 75 75 75 75 75 75 75 75 75 75 75 75 75
				75 75 75 75 75 75 75 75 75 75 75 75 75 75 75 75 75 75
				75 75 75 75 75 75 75 75 75 75 75 75 75 75 75 75 75 75
				75 75 75 75 75 75 75 75 75 75 75 75 75 75 75 75 75 75
				75 75 75 75 75 75 75 75 75 75 75 75 75 75 75 75 75 75
				75 75 75 75 75 75 75 75 75 75 75 75 75 75 75 75 75 75
				75 75 75 75 75 75 75 75 75 75 75 75 75 75 75 75 75 75
				75 75 75 75 75 75 75 75 75 75 75 75 75 75 75 75 75 75
				75 75 75 75 75 75 75 75 75 75 75 75 75 75 75 75 75 75
				75 75 75 75 75 75 75 75 75 75 75 75 75 75 75 75 75 75
				75 75 75 75 75 75 75 75 75 75 75 75 75 75 75 75 75 75
				>;

			PS_Config_Lmt_FW_Diff_N = <
				(-75) (-75) (-75) (-75) (-75) (-75) (-75) (-75) (-75) (-75) (-75) (-75) (-75) (-75) (-75) (-75) (-75) (-75)
				(-75) (-75) (-75) (-75) (-75) (-75) (-75) (-75) (-75) (-75) (-75) (-75) (-75) (-75) (-75) (-75) (-75) (-75)
				(-75) (-75) (-75) (-75) (-75) (-75) (-75) (-75) (-75) (-75) (-75) (-75) (-75) (-75) (-75) (-75) (-75) (-75)
				(-75) (-75) (-75) (-75) (-75) (-75) (-75) (-75) (-75) (-75) (-75) (-75) (-75) (-75) (-75) (-75) (-75) (-75)
				(-75) (-75) (-75) (-75) (-75) (-75) (-75) (-75) (-75) (-75) (-75) (-75) (-75) (-75) (-75) (-75) (-75) (-75)
				(-75) (-75) (-75) (-75) (-75) (-75) (-75) (-75) (-75) (-75) (-75) (-75) (-75) (-75) (-75) (-75) (-75) (-75)
				(-75) (-75) (-75) (-75) (-75) (-75) (-75) (-75) (-75) (-75) (-75) (-75) (-75) (-75) (-75) (-75) (-75) (-75)
				(-75) (-75) (-75) (-75) (-75) (-75) (-75) (-75) (-75) (-75) (-75) (-75) (-75) (-75) (-75) (-75) (-75) (-75)
				(-75) (-75) (-75) (-75) (-75) (-75) (-75) (-75) (-75) (-75) (-75) (-75) (-75) (-75) (-75) (-75) (-75) (-75)
				(-75) (-75) (-75) (-75) (-75) (-75) (-75) (-75) (-75) (-75) (-75) (-75) (-75) (-75) (-75) (-75) (-75) (-75)
				(-75) (-75) (-75) (-75) (-75) (-75) (-75) (-75) (-75) (-75) (-75) (-75) (-75) (-75) (-75) (-75) (-75) (-75)
				(-75) (-75) (-75) (-75) (-75) (-75) (-75) (-75) (-75) (-75) (-75) (-75) (-75) (-75) (-75) (-75) (-75) (-75)
				(-75) (-75) (-75) (-75) (-75) (-75) (-75) (-75) (-75) (-75) (-75) (-75) (-75) (-75) (-75) (-75) (-75) (-75)
				(-75) (-75) (-75) (-75) (-75) (-75) (-75) (-75) (-75) (-75) (-75) (-75) (-75) (-75) (-75) (-75) (-75) (-75)
				(-75) (-75) (-75) (-75) (-75) (-75) (-75) (-75) (-75) (-75) (-75) (-75) (-75) (-75) (-75) (-75) (-75) (-75)
				(-75) (-75) (-75) (-75) (-75) (-75) (-75) (-75) (-75) (-75) (-75) (-75) (-75) (-75) (-75) (-75) (-75) (-75)
				(-75) (-75) (-75) (-75) (-75) (-75) (-75) (-75) (-75) (-75) (-75) (-75) (-75) (-75) (-75) (-75) (-75) (-75)
				(-75) (-75) (-75) (-75) (-75) (-75) (-75) (-75) (-75) (-75) (-75) (-75) (-75) (-75) (-75) (-75) (-75) (-75)
				(-75) (-75) (-75) (-75) (-75) (-75) (-75) (-75) (-75) (-75) (-75) (-75) (-75) (-75) (-75) (-75) (-75) (-75)
				(-75) (-75) (-75) (-75) (-75) (-75) (-75) (-75) (-75) (-75) (-75) (-75) (-75) (-75) (-75) (-75) (-75) (-75)
				(-75) (-75) (-75) (-75) (-75) (-75) (-75) (-75) (-75) (-75) (-75) (-75) (-75) (-75) (-75) (-75) (-75) (-75)
				(-75) (-75) (-75) (-75) (-75) (-75) (-75) (-75) (-75) (-75) (-75) (-75) (-75) (-75) (-75) (-75) (-75) (-75)
				(-75) (-75) (-75) (-75) (-75) (-75) (-75) (-75) (-75) (-75) (-75) (-75) (-75) (-75) (-75) (-75) (-75) (-75)
				(-75) (-75) (-75) (-75) (-75) (-75) (-75) (-75) (-75) (-75) (-75) (-75) (-75) (-75) (-75) (-75) (-75) (-75)
				(-75) (-75) (-75) (-75) (-75) (-75) (-75) (-75) (-75) (-75) (-75) (-75) (-75) (-75) (-75) (-75) (-75) (-75)
				(-75) (-75) (-75) (-75) (-75) (-75) (-75) (-75) (-75) (-75) (-75) (-75) (-75) (-75) (-75) (-75) (-75) (-75)
				(-75) (-75) (-75) (-75) (-75) (-75) (-75) (-75) (-75) (-75) (-75) (-75) (-75) (-75) (-75) (-75) (-75) (-75)
				(-75) (-75) (-75) (-75) (-75) (-75) (-75) (-75) (-75) (-75) (-75) (-75) (-75) (-75) (-75) (-75) (-75) (-75)
				(-75) (-75) (-75) (-75) (-75) (-75) (-75) (-75) (-75) (-75) (-75) (-75) (-75) (-75) (-75) (-75) (-75) (-75)
				(-75) (-75) (-75) (-75) (-75) (-75) (-75) (-75) (-75) (-75) (-75) (-75) (-75) (-75) (-75) (-75) (-75) (-75)
				(-75) (-75) (-75) (-75) (-75) (-75) (-75) (-75) (-75) (-75) (-75) (-75) (-75) (-75) (-75) (-75) (-75) (-75)
				(-75) (-75) (-75) (-75) (-75) (-75) (-75) (-75) (-75) (-75) (-75) (-75) (-75) (-75) (-75) (-75) (-75) (-75)
				(-75) (-75) (-75) (-75) (-75) (-75) (-75) (-75) (-75) (-75) (-75) (-75) (-75) (-75) (-75) (-75) (-75) (-75)
				(-75) (-75) (-75) (-75) (-75) (-75) (-75) (-75) (-75) (-75) (-75) (-75) (-75) (-75) (-75) (-75) (-75) (-75)
				(-75) (-75) (-75) (-75) (-75) (-75) (-75) (-75) (-75) (-75) (-75) (-75) (-75) (-75) (-75) (-75) (-75) (-75)
				(-75) (-75) (-75) (-75) (-75) (-75) (-75) (-75) (-75) (-75) (-75) (-75) (-75) (-75) (-75) (-75) (-75) (-75)
				(-75) (-75) (-75) (-75) (-75) (-75) (-75) (-75) (-75) (-75) (-75) (-75) (-75) (-75) (-75) (-75) (-75) (-75)
				(-75) (-75) (-75) (-75) (-75) (-75) (-75) (-75) (-75) (-75) (-75) (-75) (-75) (-75) (-75) (-75) (-75) (-75)
				(-75) (-75) (-75) (-75) (-75) (-75) (-75) (-75) (-75) (-75) (-75) (-75) (-75) (-75) (-75) (-75) (-75) (-75)
				>;

			PS_Config_Lmt_FW_Digital_Diff_P = <
				75 75 75 75 75 75 75 75 75 75 75 75 75 75 75 75 75 75
				75 75 75 75 75 75 75 75 75 75 75 75 75 75 75 75 75 75
				75 75 75 75 75 75 75 75 75 75 75 75 75 75 75 75 75 75
				75 75 75 75 75 75 75 75 75 75 75 75 75 75 75 75 75 75
				75 75 75 75 75 75 75 75 75 75 75 75 75 75 75 75 75 75
				75 75 75 75 75 75 75 75 75 75 75 75 75 75 75 75 75 75
				75 75 75 75 75 75 75 75 75 75 75 75 75 75 75 75 75 75
				75 75 75 75 75 75 75 75 75 75 75 75 75 75 75 75 75 75
				75 75 75 75 75 75 75 75 75 75 75 75 75 75 75 75 75 75
				75 75 75 75 75 75 75 75 75 75 75 75 75 75 75 75 75 75
				75 75 75 75 75 75 75 75 75 75 75 75 75 75 75 75 75 75
				75 75 75 75 75 75 75 75 75 75 75 75 75 75 75 75 75 75
				75 75 75 75 75 75 75 75 75 75 75 75 75 75 75 75 75 75
				75 75 75 75 75 75 75 75 75 75 75 75 75 75 75 75 75 75
				75 75 75 75 75 75 75 75 75 75 75 75 75 75 75 75 75 75
				75 75 75 75 75 75 75 75 75 75 75 75 75 75 75 75 75 75
				75 75 75 75 75 75 75 75 75 75 75 75 75 75 75 75 75 75
				75 75 75 75 75 75 75 75 75 75 75 75 75 75 75 75 75 75
				75 75 75 75 75 75 75 75 75 75 75 75 75 75 75 75 75 75
				75 75 75 75 75 75 75 75 75 75 75 75 75 75 75 75 75 75
				75 75 75 75 75 75 75 75 75 75 75 75 75 75 75 75 75 75
				75 75 75 75 75 75 75 75 75 75 75 75 75 75 75 75 75 75
				75 75 75 75 75 75 75 75 75 75 75 75 75 75 75 75 75 75
				75 75 75 75 75 75 75 75 75 75 75 75 75 75 75 75 75 75
				75 75 75 75 75 75 75 75 75 75 75 75 75 75 75 75 75 75
				75 75 75 75 75 75 75 75 75 75 75 75 75 75 75 75 75 75
				75 75 75 75 75 75 75 75 75 75 75 75 75 75 75 75 75 75
				75 75 75 75 75 75 75 75 75 75 75 75 75 75 75 75 75 75
				75 75 75 75 75 75 75 75 75 75 75 75 75 75 75 75 75 75
				75 75 75 75 75 75 75 75 75 75 75 75 75 75 75 75 75 75
				75 75 75 75 75 75 75 75 75 75 75 75 75 75 75 75 75 75
				75 75 75 75 75 75 75 75 75 75 75 75 75 75 75 75 75 75
				75 75 75 75 75 75 75 75 75 75 75 75 75 75 75 75 75 75
				75 75 75 75 75 75 75 75 75 75 75 75 75 75 75 75 75 75
				75 75 75 75 75 75 75 75 75 75 75 75 75 75 75 75 75 75
				75 75 75 75 75 75 75 75 75 75 75 75 75 75 75 75 75 75
				75 75 75 75 75 75 75 75 75 75 75 75 75 75 75 75 75 75
				75 75 75 75 75 75 75 75 75 75 75 75 75 75 75 75 75 75
				75 75 75 75 75 75 75 75 75 75 75 75 75 75 75 75 75 75
				>;

			PS_Config_Lmt_FW_Digital_Diff_N = <
				(-75) (-75) (-75) (-75) (-75) (-75) (-75) (-75) (-75) (-75) (-75) (-75) (-75) (-75) (-75) (-75) (-75) (-75)
				(-75) (-75) (-75) (-75) (-75) (-75) (-75) (-75) (-75) (-75) (-75) (-75) (-75) (-75) (-75) (-75) (-75) (-75)
				(-75) (-75) (-75) (-75) (-75) (-75) (-75) (-75) (-75) (-75) (-75) (-75) (-75) (-75) (-75) (-75) (-75) (-75)
				(-75) (-75) (-75) (-75) (-75) (-75) (-75) (-75) (-75) (-75) (-75) (-75) (-75) (-75) (-75) (-75) (-75) (-75)
				(-75) (-75) (-75) (-75) (-75) (-75) (-75) (-75) (-75) (-75) (-75) (-75) (-75) (-75) (-75) (-75) (-75) (-75)
				(-75) (-75) (-75) (-75) (-75) (-75) (-75) (-75) (-75) (-75) (-75) (-75) (-75) (-75) (-75) (-75) (-75) (-75)
				(-75) (-75) (-75) (-75) (-75) (-75) (-75) (-75) (-75) (-75) (-75) (-75) (-75) (-75) (-75) (-75) (-75) (-75)
				(-75) (-75) (-75) (-75) (-75) (-75) (-75) (-75) (-75) (-75) (-75) (-75) (-75) (-75) (-75) (-75) (-75) (-75)
				(-75) (-75) (-75) (-75) (-75) (-75) (-75) (-75) (-75) (-75) (-75) (-75) (-75) (-75) (-75) (-75) (-75) (-75)
				(-75) (-75) (-75) (-75) (-75) (-75) (-75) (-75) (-75) (-75) (-75) (-75) (-75) (-75) (-75) (-75) (-75) (-75)
				(-75) (-75) (-75) (-75) (-75) (-75) (-75) (-75) (-75) (-75) (-75) (-75) (-75) (-75) (-75) (-75) (-75) (-75)
				(-75) (-75) (-75) (-75) (-75) (-75) (-75) (-75) (-75) (-75) (-75) (-75) (-75) (-75) (-75) (-75) (-75) (-75)
				(-75) (-75) (-75) (-75) (-75) (-75) (-75) (-75) (-75) (-75) (-75) (-75) (-75) (-75) (-75) (-75) (-75) (-75)
				(-75) (-75) (-75) (-75) (-75) (-75) (-75) (-75) (-75) (-75) (-75) (-75) (-75) (-75) (-75) (-75) (-75) (-75)
				(-75) (-75) (-75) (-75) (-75) (-75) (-75) (-75) (-75) (-75) (-75) (-75) (-75) (-75) (-75) (-75) (-75) (-75)
				(-75) (-75) (-75) (-75) (-75) (-75) (-75) (-75) (-75) (-75) (-75) (-75) (-75) (-75) (-75) (-75) (-75) (-75)
				(-75) (-75) (-75) (-75) (-75) (-75) (-75) (-75) (-75) (-75) (-75) (-75) (-75) (-75) (-75) (-75) (-75) (-75)
				(-75) (-75) (-75) (-75) (-75) (-75) (-75) (-75) (-75) (-75) (-75) (-75) (-75) (-75) (-75) (-75) (-75) (-75)
				(-75) (-75) (-75) (-75) (-75) (-75) (-75) (-75) (-75) (-75) (-75) (-75) (-75) (-75) (-75) (-75) (-75) (-75)
				(-75) (-75) (-75) (-75) (-75) (-75) (-75) (-75) (-75) (-75) (-75) (-75) (-75) (-75) (-75) (-75) (-75) (-75)
				(-75) (-75) (-75) (-75) (-75) (-75) (-75) (-75) (-75) (-75) (-75) (-75) (-75) (-75) (-75) (-75) (-75) (-75)
				(-75) (-75) (-75) (-75) (-75) (-75) (-75) (-75) (-75) (-75) (-75) (-75) (-75) (-75) (-75) (-75) (-75) (-75)
				(-75) (-75) (-75) (-75) (-75) (-75) (-75) (-75) (-75) (-75) (-75) (-75) (-75) (-75) (-75) (-75) (-75) (-75)
				(-75) (-75) (-75) (-75) (-75) (-75) (-75) (-75) (-75) (-75) (-75) (-75) (-75) (-75) (-75) (-75) (-75) (-75)
				(-75) (-75) (-75) (-75) (-75) (-75) (-75) (-75) (-75) (-75) (-75) (-75) (-75) (-75) (-75) (-75) (-75) (-75)
				(-75) (-75) (-75) (-75) (-75) (-75) (-75) (-75) (-75) (-75) (-75) (-75) (-75) (-75) (-75) (-75) (-75) (-75)
				(-75) (-75) (-75) (-75) (-75) (-75) (-75) (-75) (-75) (-75) (-75) (-75) (-75) (-75) (-75) (-75) (-75) (-75)
				(-75) (-75) (-75) (-75) (-75) (-75) (-75) (-75) (-75) (-75) (-75) (-75) (-75) (-75) (-75) (-75) (-75) (-75)
				(-75) (-75) (-75) (-75) (-75) (-75) (-75) (-75) (-75) (-75) (-75) (-75) (-75) (-75) (-75) (-75) (-75) (-75)
				(-75) (-75) (-75) (-75) (-75) (-75) (-75) (-75) (-75) (-75) (-75) (-75) (-75) (-75) (-75) (-75) (-75) (-75)
				(-75) (-75) (-75) (-75) (-75) (-75) (-75) (-75) (-75) (-75) (-75) (-75) (-75) (-75) (-75) (-75) (-75) (-75)
				(-75) (-75) (-75) (-75) (-75) (-75) (-75) (-75) (-75) (-75) (-75) (-75) (-75) (-75) (-75) (-75) (-75) (-75)
				(-75) (-75) (-75) (-75) (-75) (-75) (-75) (-75) (-75) (-75) (-75) (-75) (-75) (-75) (-75) (-75) (-75) (-75)
				(-75) (-75) (-75) (-75) (-75) (-75) (-75) (-75) (-75) (-75) (-75) (-75) (-75) (-75) (-75) (-75) (-75) (-75)
				(-75) (-75) (-75) (-75) (-75) (-75) (-75) (-75) (-75) (-75) (-75) (-75) (-75) (-75) (-75) (-75) (-75) (-75)
				(-75) (-75) (-75) (-75) (-75) (-75) (-75) (-75) (-75) (-75) (-75) (-75) (-75) (-75) (-75) (-75) (-75) (-75)
				(-75) (-75) (-75) (-75) (-75) (-75) (-75) (-75) (-75) (-75) (-75) (-75) (-75) (-75) (-75) (-75) (-75) (-75)
				(-75) (-75) (-75) (-75) (-75) (-75) (-75) (-75) (-75) (-75) (-75) (-75) (-75) (-75) (-75) (-75) (-75) (-75)
				(-75) (-75) (-75) (-75) (-75) (-75) (-75) (-75) (-75) (-75) (-75) (-75) (-75) (-75) (-75) (-75) (-75) (-75)
				>;

			PS_Config_Diff_Test_Frame = <50>;
			PS_Config_Digital_Diff_Test_Frame = <50>;
		};

		/* for Xiaomi flourite NT38771 TM6.83" panel module */
		novatek-mp-criteria-59AC@0 {
			#address-cells = <1>;
			#size-cells = <0>;
			compatible = "novatek-mp-criteria-59AC";

			/* MP Criteria */
			PS_Config_Lmt_Short_TXRX_P = <
				3500 3500 3500 3500 3500 3500 3500 3500 3500 3500 3500 3500 3500 3500 3500 3500 3500 3500
				3500 3500 3500 3500 3500 3500 3500 3500 3500 3500 3500 3500 3500 3500 3500 3500 3500 3500
				3500 3500 3500 3500 3500 3500 3500 3500 3500 3500 3500 3500 3500 3500 3500 3500 3500 3500
				3500 3500 3500 3500 3500 3500 3500 3500 3500 3500 3500 3500 3500 3500 3500 3500 3500 3500
				3500 3500 3500 3500 3500 3500 3500 3500 3500 3500 3500 3500 3500 3500 3500 3500 3500 3500
				3500 3500 3500 3500 3500 3500 3500 3500 3500 3500 3500 3500 3500 3500 3500 3500 3500 3500
				3500 3500 3500 3500 3500 3500 3500 3500 3500 3500 3500 3500 3500 3500 3500 3500 3500 3500
				3500 3500 3500 3500 3500 3500 3500 3500 3500 3500 3500 3500 3500 3500 3500 3500 3500 3500
				3500 3500 3500 3500 3500 3500 3500 3500 3500 3500 3500 3500 3500 3500 3500 3500 3500 3500
				3500 3500 3500 3500 3500 3500 3500 3500 3500 3500 3500 3500 3500 3500 3500 3500 3500 3500
				3500 3500 3500 3500 3500 3500 3500 3500 3500 3500 3500 3500 3500 3500 3500 3500 3500 3500
				3500 3500 3500 3500 3500 3500 3500 3500 3500 3500 3500 3500 3500 3500 3500 3500 3500 3500
				3500 3500 3500 3500 3500 3500 3500 3500 3500 3500 3500 3500 3500 3500 3500 3500 3500 3500
				3500 3500 3500 3500 3500 3500 3500 3500 3500 3500 3500 3500 3500 3500 3500 3500 3500 3500
				3500 3500 3500 3500 3500 3500 3500 3500 3500 3500 3500 3500 3500 3500 3500 3500 3500 3500
				3500 3500 3500 3500 3500 3500 3500 3500 3500 3500 3500 3500 3500 3500 3500 3500 3500 3500
				3500 3500 3500 3500 3500 3500 3500 3500 3500 3500 3500 3500 3500 3500 3500 3500 3500 3500
				3500 3500 3500 3500 3500 3500 3500 3500 3500 3500 3500 3500 3500 3500 3500 3500 3500 3500
				3500 3500 3500 3500 3500 3500 3500 3500 3500 3500 3500 3500 3500 3500 3500 3500 3500 3500
				3500 3500 3500 3500 3500 3500 3500 3500 3500 3500 3500 3500 3500 3500 3500 3500 3500 3500
				3500 3500 3500 3500 3500 3500 3500 3500 3500 3500 3500 3500 3500 3500 3500 3500 3500 3500
				3500 3500 3500 3500 3500 3500 3500 3500 3500 3500 3500 3500 3500 3500 3500 3500 3500 3500
				3500 3500 3500 3500 3500 3500 3500 3500 3500 3500 3500 3500 3500 3500 3500 3500 3500 3500
				3500 3500 3500 3500 3500 3500 3500 3500 3500 3500 3500 3500 3500 3500 3500 3500 3500 3500
				3500 3500 3500 3500 3500 3500 3500 3500 3500 3500 3500 3500 3500 3500 3500 3500 3500 3500
				3500 3500 3500 3500 3500 3500 3500 3500 3500 3500 3500 3500 3500 3500 3500 3500 3500 3500
				3500 3500 3500 3500 3500 3500 3500 3500 3500 3500 3500 3500 3500 3500 3500 3500 3500 3500
				3500 3500 3500 3500 3500 3500 3500 3500 3500 3500 3500 3500 3500 3500 3500 3500 3500 3500
				3500 3500 3500 3500 3500 3500 3500 3500 3500 3500 3500 3500 3500 3500 3500 3500 3500 3500
				3500 3500 3500 3500 3500 3500 3500 3500 3500 3500 3500 3500 3500 3500 3500 3500 3500 3500
				3500 3500 3500 3500 3500 3500 3500 3500 3500 3500 3500 3500 3500 3500 3500 3500 3500 3500
				3500 3500 3500 3500 3500 3500 3500 3500 3500 3500 3500 3500 3500 3500 3500 3500 3500 3500
				3500 3500 3500 3500 3500 3500 3500 3500 3500 3500 3500 3500 3500 3500 3500 3500 3500 3500
				3500 3500 3500 3500 3500 3500 3500 3500 3500 3500 3500 3500 3500 3500 3500 3500 3500 3500
				3500 3500 3500 3500 3500 3500 3500 3500 3500 3500 3500 3500 3500 3500 3500 3500 3500 3500
				3500 3500 3500 3500 3500 3500 3500 3500 3500 3500 3500 3500 3500 3500 3500 3500 3500 3500
				3500 3500 3500 3500 3500 3500 3500 3500 3500 3500 3500 3500 3500 3500 3500 3500 3500 3500
				3500 3500 3500 3500 3500 3500 3500 3500 3500 3500 3500 3500 3500 3500 3500 3500 3500 3500
				3500 3500 3500 3500 3500 3500 3500 3500 3500 3500 3500 3500 3500 3500 3500 3500 3500 3500
				>;

			PS_Config_Lmt_Short_TXRX_N = <
				1900 1900 1900 1900 1900 1900 1900 1900 1900 1900 1900 1900 1900 1900 1900 1900 1900 1900
				1900 1900 1900 1900 1900 1900 1900 1900 1900 1900 1900 1900 1900 1900 1900 1900 1900 1900
				1900 1900 1900 1900 1900 1900 1900 1900 1900 1900 1900 1900 1900 1900 1900 1900 1900 1900
				1900 1900 1900 1900 1900 1900 1900 1900 1900 1900 1900 1900 1900 1900 1900 1900 1900 1900
				1900 1900 1900 1900 1900 1900 1900 1900 1900 1900 1900 1900 1900 1900 1900 1900 1900 1900
				1900 1900 1900 1900 1900 1900 1900 1900 1900 1900 1900 1900 1900 1900 1900 1900 1900 1900
				1900 1900 1900 1900 1900 1900 1900 1900 1900 1900 1900 1900 1900 1900 1900 1900 1900 1900
				1900 1900 1900 1900 1900 1900 1900 1900 1900 1900 1900 1900 1900 1900 1900 1900 1900 1900
				1900 1900 1900 1900 1900 1900 1900 1900 1900 1900 1900 1900 1900 1900 1900 1900 1900 1900
				1900 1900 1900 1900 1900 1900 1900 1900 1900 1900 1900 1900 1900 1900 1900 1900 1900 1900
				1900 1900 1900 1900 1900 1900 1900 1900 1900 1900 1900 1900 1900 1900 1900 1900 1900 1900
				1900 1900 1900 1900 1900 1900 1900 1900 1900 1900 1900 1900 1900 1900 1900 1900 1900 1900
				1900 1900 1900 1900 1900 1900 1900 1900 1900 1900 1900 1900 1900 1900 1900 1900 1900 1900
				1900 1900 1900 1900 1900 1900 1900 1900 1900 1900 1900 1900 1900 1900 1900 1900 1900 1900
				1900 1900 1900 1900 1900 1900 1900 1900 1900 1900 1900 1900 1900 1900 1900 1900 1900 1900
				1900 1900 1900 1900 1900 1900 1900 1900 1900 1900 1900 1900 1900 1900 1900 1900 1900 1900
				1900 1900 1900 1900 1900 1900 1900 1900 1900 1900 1900 1900 1900 1900 1900 1900 1900 1900
				1900 1900 1900 1900 1900 1900 1900 1900 1900 1900 1900 1900 1900 1900 1900 1900 1900 1900
				1900 1900 1900 1900 1900 1900 1900 1900 1900 1900 1900 1900 1900 1900 1900 1900 1900 1900
				1900 1900 1900 1900 1900 1900 1900 1900 1900 1900 1900 1900 1900 1900 1900 1900 1900 1900
				1900 1900 1900 1900 1900 1900 1900 1900 1900 1900 1900 1900 1900 1900 1900 1900 1900 1900
				1900 1900 1900 1900 1900 1900 1900 1900 1900 1900 1900 1900 1900 1900 1900 1900 1900 1900
				1900 1900 1900 1900 1900 1900 1900 1900 1900 1900 1900 1900 1900 1900 1900 1900 1900 1900
				1900 1900 1900 1900 1900 1900 1900 1900 1900 1900 1900 1900 1900 1900 1900 1900 1900 1900
				1900 1900 1900 1900 1900 1900 1900 1900 1900 1900 1900 1900 1900 1900 1900 1900 1900 1900
				1900 1900 1900 1900 1900 1900 1900 1900 1900 1900 1900 1900 1900 1900 1900 1900 1900 1900
				1900 1900 1900 1900 1900 1900 1900 1900 1900 1900 1900 1900 1900 1900 1900 1900 1900 1900
				1900 1900 1900 1900 1900 1900 1900 1900 1900 1900 1900 1900 1900 1900 1900 1900 1900 1900
				1900 1900 1900 1900 1900 1900 1900 1900 1900 1900 1900 1900 1900 1900 1900 1900 1900 1900
				1900 1900 1900 1900 1900 1900 1900 1900 1900 1900 1900 1900 1900 1900 1900 1900 1900 1900
				1900 1900 1900 1900 1900 1900 1900 1900 1900 1900 1900 1900 1900 1900 1900 1900 1900 1900
				1900 1900 1900 1900 1900 1900 1900 1900 1900 1900 1900 1900 1900 1900 1900 1900 1900 1900
				1900 1900 1900 1900 1900 1900 1900 1900 1900 1900 1900 1900 1900 1900 1900 1900 1900 1900
				1900 1900 1900 1900 1900 1900 1900 1900 1900 1900 1900 1900 1900 1900 1900 1900 1900 1900
				1900 1900 1900 1900 1900 1900 1900 1900 1900 1900 1900 1900 1900 1900 1900 1900 1900 1900
				1900 1900 1900 1900 1900 1900 1900 1900 1900 1900 1900 1900 1900 1900 1900 1900 1900 1900
				1900 1900 1900 1900 1900 1900 1900 1900 1900 1900 1900 1900 1900 1900 1900 1900 1900 1900
				1900 1900 1900 1900 1900 1900 1900 1900 1900 1900 1900 1900 1900 1900 1900 1900 1900 1900
				1900 1900 1900 1900 1900 1900 1900 1900 1900 1900 1900 1900 1900 1900 1900 1900 1900 1900
				>;

			PS_Config_Lmt_Short_TXTX_P = <
				3500 3500 3500 3500 3500 3500 3500 3500 3500 3500 3500 3500 3500 3500 3500 3500 3500 3500
				>;

			PS_Config_Lmt_Short_TXTX_N = <
				1900 1900 1900 1900 1900 1900 1900 1900 1900 1900 1900 1900 1900 1900 1900 1900 1900 1900
				>;

			PS_Config_Lmt_Short_RXRX_P = <
				3500
				3500
				3500
				3500
				3500
				3500
				3500
				3500
				3500
				3500
				3500
				3500
				3500
				3500
				3500
				3500
				3500
				3500
				3500
				3500
				3500
				3500
				3500
				3500
				3500
				3500
				3500
				3500
				3500
				3500
				3500
				3500
				3500
				3500
				3500
				3500
				3500
				3500
				3500
				>;

			PS_Config_Lmt_Short_RXRX_N = <
				1900
				1900
				1900
				1900
				1900
				1900
				1900
				1900
				1900
				1900
				1900
				1900
				1900
				1900
				1900
				1900
				1900
				1900
				1900
				1900
				1900
				1900
				1900
				1900
				1900
				1900
				1900
				1900
				1900
				1900
				1900
				1900
				1900
				1900
				1900
				1900
				1900
				1900
				1900
				>;

			PS_Config_Lmt_Open_Mutual_P = <
				65535 5000 5000 5000 5000 5000 5000 5000 5000 5000 5000 5000 5000 5000 5000 5000 5000 65535
				5000 5000 5000 5000 5000 5000 5000 5000 5000 5000 5000 5000 5000 5000 5000 5000 5000 5000
				5000 5000 5000 5000 5000 5000 5000 5000 5000 5000 5000 5000 5000 5000 5000 5000 5000 5000
				5000 5000 5000 5000 5000 5000 5000 5000 5000 5000 5000 5000 5000 5000 5000 5000 5000 5000
				5000 5000 5000 5000 5000 5000 5000 5000 5000 5000 5000 5000 5000 5000 5000 5000 5000 5000
				5000 5000 5000 5000 5000 5000 5000 5000 5000 5000 5000 5000 5000 5000 5000 5000 5000 5000
				5000 5000 5000 5000 5000 5000 5000 5000 5000 5000 5000 5000 5000 5000 5000 5000 5000 5000
				5000 5000 5000 5000 5000 5000 5000 5000 5000 5000 5000 5000 5000 5000 5000 5000 5000 5000
				5000 5000 5000 5000 5000 5000 5000 5000 5000 5000 5000 5000 5000 5000 5000 5000 5000 5000
				5000 5000 5000 5000 5000 5000 5000 5000 5000 5000 5000 5000 5000 5000 5000 5000 5000 5000
				5000 5000 5000 5000 5000 5000 5000 5000 5000 5000 5000 5000 5000 5000 5000 5000 5000 5000
				5000 5000 5000 5000 5000 5000 5000 5000 5000 5000 5000 5000 5000 5000 5000 5000 5000 5000
				5000 5000 5000 5000 5000 5000 5000 5000 5000 5000 5000 5000 5000 5000 5000 5000 5000 5000
				5000 5000 5000 5000 5000 5000 5000 5000 5000 5000 5000 5000 5000 5000 5000 5000 5000 5000
				5000 5000 5000 5000 5000 5000 5000 5000 5000 5000 5000 5000 5000 5000 5000 5000 5000 5000
				5000 5000 5000 5000 5000 5000 5000 5000 5000 5000 5000 5000 5000 5000 5000 5000 5000 5000
				5000 5000 5000 5000 5000 5000 5000 5000 5000 5000 5000 5000 5000 5000 5000 5000 5000 5000
				5000 5000 5000 5000 5000 5000 5000 5000 5000 5000 5000 5000 5000 5000 5000 5000 5000 5000
				5000 5000 5000 5000 5000 5000 5000 5000 5000 5000 5000 5000 5000 5000 5000 5000 5000 5000
				5000 5000 5000 5000 5000 5000 5000 5000 5000 5000 5000 5000 5000 5000 5000 5000 5000 5000
				5000 5000 5000 5000 5000 5000 5000 5000 5000 5000 5000 5000 5000 5000 5000 5000 5000 5000
				5000 5000 5000 5000 5000 5000 5000 5000 5000 5000 5000 5000 5000 5000 5000 5000 5000 5000
				5000 5000 5000 5000 5000 5000 5000 5000 5000 5000 5000 5000 5000 5000 5000 5000 5000 5000
				5000 5000 5000 5000 5000 5000 5000 5000 5000 5000 5000 5000 5000 5000 5000 5000 5000 5000
				5000 5000 5000 5000 5000 5000 5000 5000 5000 5000 5000 5000 5000 5000 5000 5000 5000 5000
				5000 5000 5000 5000 5000 5000 5000 5000 5000 5000 5000 5000 5000 5000 5000 5000 5000 5000
				5000 5000 5000 5000 5000 5000 5000 5000 5000 5000 5000 5000 5000 5000 5000 5000 5000 5000
				5000 5000 5000 5000 5000 5000 5000 5000 5000 5000 5000 5000 5000 5000 5000 5000 5000 5000
				5000 5000 5000 5000 5000 5000 5000 5000 5000 5000 5000 5000 5000 5000 5000 5000 5000 5000
				5000 5000 5000 5000 5000 5000 5000 5000 5000 5000 5000 5000 5000 5000 5000 5000 5000 5000
				5000 5000 5000 5000 5000 5000 5000 5000 5000 5000 5000 5000 5000 5000 5000 5000 5000 5000
				5000 5000 5000 5000 5000 5000 5000 5000 5000 5000 5000 5000 5000 5000 5000 5000 5000 5000
				5000 5000 5000 5000 5000 5000 5000 5000 5000 5000 5000 5000 5000 5000 5000 5000 5000 5000
				5000 5000 5000 5000 5000 5000 5000 5000 5000 5000 5000 5000 5000 5000 5000 5000 5000 5000
				5000 5000 5000 5000 5000 5000 5000 5000 5000 5000 5000 5000 5000 5000 5000 5000 5000 5000
				5000 5000 5000 5000 5000 5000 5000 5000 5000 5000 5000 5000 5000 5000 5000 5000 5000 5000
				5000 5000 5000 5000 5000 5000 5000 5000 5000 5000 5000 5000 5000 5000 5000 5000 5000 5000
				5000 5000 5000 5000 5000 5000 5000 5000 5000 5000 5000 5000 5000 5000 5000 5000 5000 5000
				65535 5000 5000 5000 5000 5000 5000 5000 5000 5000 5000 5000 5000 5000 5000 5000 5000 65535
				>;

			PS_Config_Lmt_Open_Mutual_N = <
				(-65535) 100 100 100 100 100 100 100 100 100 100 100 100 100 100 100 100 (-65535)
				100 100 100 100 100 100 100 100 100 100 100 100 100 100 100 100 100 100
				100 100 100 100 100 100 100 100 100 100 100 100 100 100 100 100 100 100
				100 100 100 100 100 100 100 100 100 100 100 100 100 100 100 100 100 100
				100 100 100 100 100 100 100 100 100 100 100 100 100 100 100 100 100 100
				100 100 100 100 100 100 100 100 100 100 100 100 100 100 100 100 100 100
				100 100 100 100 100 100 100 100 100 100 100 100 100 100 100 100 100 100
				100 100 100 100 100 100 100 100 100 100 100 100 100 100 100 100 100 100
				100 100 100 100 100 100 100 100 100 100 100 100 100 100 100 100 100 100
				100 100 100 100 100 100 100 100 100 100 100 100 100 100 100 100 100 100
				100 100 100 100 100 100 100 100 100 100 100 100 100 100 100 100 100 100
				100 100 100 100 100 100 100 100 100 100 100 100 100 100 100 100 100 100
				100 100 100 100 100 100 100 100 100 100 100 100 100 100 100 100 100 100
				100 100 100 100 100 100 100 100 100 100 100 100 100 100 100 100 100 100
				100 100 100 100 100 100 100 100 100 100 100 100 100 100 100 100 100 100
				100 100 100 100 100 100 100 100 100 100 100 100 100 100 100 100 100 100
				100 100 100 100 100 100 100 100 100 100 100 100 100 100 100 100 100 100
				100 100 100 100 100 100 100 100 100 100 100 100 100 100 100 100 100 100
				100 100 100 100 100 100 100 100 100 100 100 100 100 100 100 100 100 100
				100 100 100 100 100 100 100 100 100 100 100 100 100 100 100 100 100 100
				100 100 100 100 100 100 100 100 100 100 100 100 100 100 100 100 100 100
				100 100 100 100 100 100 100 100 100 100 100 100 100 100 100 100 100 100
				100 100 100 100 100 100 100 100 100 100 100 100 100 100 100 100 100 100
				100 100 100 100 100 100 100 100 100 100 100 100 100 100 100 100 100 100
				100 100 100 100 100 100 100 100 100 100 100 100 100 100 100 100 100 100
				100 100 100 100 100 100 100 100 100 100 100 100 100 100 100 100 100 100
				100 100 100 100 100 100 100 100 100 100 100 100 100 100 100 100 100 100
				100 100 100 100 100 100 100 100 100 100 100 100 100 100 100 100 100 100
				100 100 100 100 100 100 100 100 100 100 100 100 100 100 100 100 100 100
				100 100 100 100 100 100 100 100 100 100 100 100 100 100 100 100 100 100
				100 100 100 100 100 100 100 100 100 100 100 100 100 100 100 100 100 100
				100 100 100 100 100 100 100 100 100 100 100 100 100 100 100 100 100 100
				100 100 100 100 100 100 100 100 100 100 100 100 100 100 100 100 100 100
				100 100 100 100 100 100 100 100 100 100 100 100 100 100 100 100 100 100
				100 100 100 100 100 100 100 100 100 100 100 100 100 100 100 100 100 100
				100 100 100 100 100 100 100 100 100 100 100 100 100 100 100 100 100 100
				100 100 100 100 100 100 100 100 100 100 100 100 100 100 100 100 100 100
				100 100 100 100 100 100 100 100 100 100 100 100 100 100 100 100 100 100
				(-65535) 100 100 100 100 100 100 100 100 100 100 100 100 100 100 100 100 (-65535)
				>;

			PS_Config_Lmt_Open_SelfTX_P = <
				5000 5000 5000 5000 5000 5000 5000 5000 5000 5000 5000 5000 5000 5000 5000 5000 5000 5000
				>;

			PS_Config_Lmt_Open_SelfTX_N = <
				100 100 100 100 100 100 100 100 100 100 100 100 100 100 100 100 100 100
				>;

			PS_Config_Lmt_Open_SelfRX_P = <
				5000
				5000
				5000
				5000
				5000
				5000
				5000
				5000
				5000
				5000
				5000
				5000
				5000
				5000
				5000
				5000
				5000
				5000
				5000
				5000
				5000
				5000
				5000
				5000
				5000
				5000
				5000
				5000
				5000
				5000
				5000
				5000
				5000
				5000
				5000
				5000
				5000
				5000
				5000
				>;

			PS_Config_Lmt_Open_SelfRX_N = <
				100
				100
				100
				100
				100
				100
				100
				100
				100
				100
				100
				100
				100
				100
				100
				100
				100
				100
				100
				100
				100
				100
				100
				100
				100
				100
				100
				100
				100
				100
				100
				100
				100
				100
				100
				100
				100
				100
				100
				>;

			PS_Config_Lmt_FW_Rawdata_P = <
				5000 5000 5000 5000 5000 5000 5000 5000 5000 5000 5000 5000 5000 5000 5000 5000 5000 5000
				5000 5000 5000 5000 5000 5000 5000 5000 5000 5000 5000 5000 5000 5000 5000 5000 5000 5000
				5000 5000 5000 5000 5000 5000 5000 5000 5000 5000 5000 5000 5000 5000 5000 5000 5000 5000
				5000 5000 5000 5000 5000 5000 5000 5000 5000 5000 5000 5000 5000 5000 5000 5000 5000 5000
				5000 5000 5000 5000 5000 5000 5000 5000 5000 5000 5000 5000 5000 5000 5000 5000 5000 5000
				5000 5000 5000 5000 5000 5000 5000 5000 5000 5000 5000 5000 5000 5000 5000 5000 5000 5000
				5000 5000 5000 5000 5000 5000 5000 5000 5000 5000 5000 5000 5000 5000 5000 5000 5000 5000
				5000 5000 5000 5000 5000 5000 5000 5000 5000 5000 5000 5000 5000 5000 5000 5000 5000 5000
				5000 5000 5000 5000 5000 5000 5000 5000 5000 5000 5000 5000 5000 5000 5000 5000 5000 5000
				5000 5000 5000 5000 5000 5000 5000 5000 5000 5000 5000 5000 5000 5000 5000 5000 5000 5000
				5000 5000 5000 5000 5000 5000 5000 5000 5000 5000 5000 5000 5000 5000 5000 5000 5000 5000
				5000 5000 5000 5000 5000 5000 5000 5000 5000 5000 5000 5000 5000 5000 5000 5000 5000 5000
				5000 5000 5000 5000 5000 5000 5000 5000 5000 5000 5000 5000 5000 5000 5000 5000 5000 5000
				5000 5000 5000 5000 5000 5000 5000 5000 5000 5000 5000 5000 5000 5000 5000 5000 5000 5000
				5000 5000 5000 5000 5000 5000 5000 5000 5000 5000 5000 5000 5000 5000 5000 5000 5000 5000
				5000 5000 5000 5000 5000 5000 5000 5000 5000 5000 5000 5000 5000 5000 5000 5000 5000 5000
				5000 5000 5000 5000 5000 5000 5000 5000 5000 5000 5000 5000 5000 5000 5000 5000 5000 5000
				5000 5000 5000 5000 5000 5000 5000 5000 5000 5000 5000 5000 5000 5000 5000 5000 5000 5000
				5000 5000 5000 5000 5000 5000 5000 5000 5000 5000 5000 5000 5000 5000 5000 5000 5000 5000
				5000 5000 5000 5000 5000 5000 5000 5000 5000 5000 5000 5000 5000 5000 5000 5000 5000 5000
				5000 5000 5000 5000 5000 5000 5000 5000 5000 5000 5000 5000 5000 5000 5000 5000 5000 5000
				5000 5000 5000 5000 5000 5000 5000 5000 5000 5000 5000 5000 5000 5000 5000 5000 5000 5000
				5000 5000 5000 5000 5000 5000 5000 5000 5000 5000 5000 5000 5000 5000 5000 5000 5000 5000
				5000 5000 5000 5000 5000 5000 5000 5000 5000 5000 5000 5000 5000 5000 5000 5000 5000 5000
				5000 5000 5000 5000 5000 5000 5000 5000 5000 5000 5000 5000 5000 5000 5000 5000 5000 5000
				5000 5000 5000 5000 5000 5000 5000 5000 5000 5000 5000 5000 5000 5000 5000 5000 5000 5000
				5000 5000 5000 5000 5000 5000 5000 5000 5000 5000 5000 5000 5000 5000 5000 5000 5000 5000
				5000 5000 5000 5000 5000 5000 5000 5000 5000 5000 5000 5000 5000 5000 5000 5000 5000 5000
				5000 5000 5000 5000 5000 5000 5000 5000 5000 5000 5000 5000 5000 5000 5000 5000 5000 5000
				5000 5000 5000 5000 5000 5000 5000 5000 5000 5000 5000 5000 5000 5000 5000 5000 5000 5000
				5000 5000 5000 5000 5000 5000 5000 5000 5000 5000 5000 5000 5000 5000 5000 5000 5000 5000
				5000 5000 5000 5000 5000 5000 5000 5000 5000 5000 5000 5000 5000 5000 5000 5000 5000 5000
				5000 5000 5000 5000 5000 5000 5000 5000 5000 5000 5000 5000 5000 5000 5000 5000 5000 5000
				5000 5000 5000 5000 5000 5000 5000 5000 5000 5000 5000 5000 5000 5000 5000 5000 5000 5000
				5000 5000 5000 5000 5000 5000 5000 5000 5000 5000 5000 5000 5000 5000 5000 5000 5000 5000
				5000 5000 5000 5000 5000 5000 5000 5000 5000 5000 5000 5000 5000 5000 5000 5000 5000 5000
				5000 5000 5000 5000 5000 5000 5000 5000 5000 5000 5000 5000 5000 5000 5000 5000 5000 5000
				5000 5000 5000 5000 5000 5000 5000 5000 5000 5000 5000 5000 5000 5000 5000 5000 5000 5000
				5000 5000 5000 5000 5000 5000 5000 5000 5000 5000 5000 5000 5000 5000 5000 5000 5000 5000
				>;

			PS_Config_Lmt_FW_Rawdata_N = <
				1000 1000 1000 1000 1000 1000 1000 1000 1000 1000 1000 1000 1000 1000 1000 1000 1000 1000
				1000 1000 1000 1000 1000 1000 1000 1000 1000 1000 1000 1000 1000 1000 1000 1000 1000 1000
				1000 1000 1000 1000 1000 1000 1000 1000 1000 1000 1000 1000 1000 1000 1000 1000 1000 1000
				1000 1000 1000 1000 1000 1000 1000 1000 1000 1000 1000 1000 1000 1000 1000 1000 1000 1000
				1000 1000 1000 1000 1000 1000 1000 1000 1000 1000 1000 1000 1000 1000 1000 1000 1000 1000
				1000 1000 1000 1000 1000 1000 1000 1000 1000 1000 1000 1000 1000 1000 1000 1000 1000 1000
				1000 1000 1000 1000 1000 1000 1000 1000 1000 1000 1000 1000 1000 1000 1000 1000 1000 1000
				1000 1000 1000 1000 1000 1000 1000 1000 1000 1000 1000 1000 1000 1000 1000 1000 1000 1000
				1000 1000 1000 1000 1000 1000 1000 1000 1000 1000 1000 1000 1000 1000 1000 1000 1000 1000
				1000 1000 1000 1000 1000 1000 1000 1000 1000 1000 1000 1000 1000 1000 1000 1000 1000 1000
				1000 1000 1000 1000 1000 1000 1000 1000 1000 1000 1000 1000 1000 1000 1000 1000 1000 1000
				1000 1000 1000 1000 1000 1000 1000 1000 1000 1000 1000 1000 1000 1000 1000 1000 1000 1000
				1000 1000 1000 1000 1000 1000 1000 1000 1000 1000 1000 1000 1000 1000 1000 1000 1000 1000
				1000 1000 1000 1000 1000 1000 1000 1000 1000 1000 1000 1000 1000 1000 1000 1000 1000 1000
				1000 1000 1000 1000 1000 1000 1000 1000 1000 1000 1000 1000 1000 1000 1000 1000 1000 1000
				1000 1000 1000 1000 1000 1000 1000 1000 1000 1000 1000 1000 1000 1000 1000 1000 1000 1000
				1000 1000 1000 1000 1000 1000 1000 1000 1000 1000 1000 1000 1000 1000 1000 1000 1000 1000
				1000 1000 1000 1000 1000 1000 1000 1000 1000 1000 1000 1000 1000 1000 1000 1000 1000 1000
				1000 1000 1000 1000 1000 1000 1000 1000 1000 1000 1000 1000 1000 1000 1000 1000 1000 1000
				1000 1000 1000 1000 1000 1000 1000 1000 1000 1000 1000 1000 1000 1000 1000 1000 1000 1000
				1000 1000 1000 1000 1000 1000 1000 1000 1000 1000 1000 1000 1000 1000 1000 1000 1000 1000
				1000 1000 1000 1000 1000 1000 1000 1000 1000 1000 1000 1000 1000 1000 1000 1000 1000 1000
				1000 1000 1000 1000 1000 1000 1000 1000 1000 1000 1000 1000 1000 1000 1000 1000 1000 1000
				1000 1000 1000 1000 1000 1000 1000 1000 1000 1000 1000 1000 1000 1000 1000 1000 1000 1000
				1000 1000 1000 1000 1000 1000 1000 1000 1000 1000 1000 1000 1000 1000 1000 1000 1000 1000
				1000 1000 1000 1000 1000 1000 1000 1000 1000 1000 1000 1000 1000 1000 1000 1000 1000 1000
				1000 1000 1000 1000 1000 1000 1000 1000 1000 1000 1000 1000 1000 1000 1000 1000 1000 1000
				1000 1000 1000 1000 1000 1000 1000 1000 1000 1000 1000 1000 1000 1000 1000 1000 1000 1000
				1000 1000 1000 1000 1000 1000 1000 1000 1000 1000 1000 1000 1000 1000 1000 1000 1000 1000
				1000 1000 1000 1000 1000 1000 1000 1000 1000 1000 1000 1000 1000 1000 1000 1000 1000 1000
				1000 1000 1000 1000 1000 1000 1000 1000 1000 1000 1000 1000 1000 1000 1000 1000 1000 1000
				1000 1000 1000 1000 1000 1000 1000 1000 1000 1000 1000 1000 1000 1000 1000 1000 1000 1000
				1000 1000 1000 1000 1000 1000 1000 1000 1000 1000 1000 1000 1000 1000 1000 1000 1000 1000
				1000 1000 1000 1000 1000 1000 1000 1000 1000 1000 1000 1000 1000 1000 1000 1000 1000 1000
				1000 1000 1000 1000 1000 1000 1000 1000 1000 1000 1000 1000 1000 1000 1000 1000 1000 1000
				1000 1000 1000 1000 1000 1000 1000 1000 1000 1000 1000 1000 1000 1000 1000 1000 1000 1000
				1000 1000 1000 1000 1000 1000 1000 1000 1000 1000 1000 1000 1000 1000 1000 1000 1000 1000
				1000 1000 1000 1000 1000 1000 1000 1000 1000 1000 1000 1000 1000 1000 1000 1000 1000 1000
				1000 1000 1000 1000 1000 1000 1000 1000 1000 1000 1000 1000 1000 1000 1000 1000 1000 1000
				>;

			PS_Config_Lmt_FW_CC_P = <
				80 80 80 80 80 80 80 80 80 80 80 80 80 80 80 80 80 80
				80 80 80 80 80 80 80 80 80 80 80 80 80 80 80 80 80 80
				80 80 80 80 80 80 80 80 80 80 80 80 80 80 80 80 80 80
				80 80 80 80 80 80 80 80 80 80 80 80 80 80 80 80 80 80
				80 80 80 80 80 80 80 80 80 80 80 80 80 80 80 80 80 80
				80 80 80 80 80 80 80 80 80 80 80 80 80 80 80 80 80 80
				80 80 80 80 80 80 80 80 80 80 80 80 80 80 80 80 80 80
				80 80 80 80 80 80 80 80 80 80 80 80 80 80 80 80 80 80
				80 80 80 80 80 80 80 80 80 80 80 80 80 80 80 80 80 80
				80 80 80 80 80 80 80 80 80 80 80 80 80 80 80 80 80 80
				80 80 80 80 80 80 80 80 80 80 80 80 80 80 80 80 80 80
				80 80 80 80 80 80 80 80 80 80 80 80 80 80 80 80 80 80
				80 80 80 80 80 80 80 80 80 80 80 80 80 80 80 80 80 80
				80 80 80 80 80 80 80 80 80 80 80 80 80 80 80 80 80 80
				80 80 80 80 80 80 80 80 80 80 80 80 80 80 80 80 80 80
				80 80 80 80 80 80 80 80 80 80 80 80 80 80 80 80 80 80
				80 80 80 80 80 80 80 80 80 80 80 80 80 80 80 80 80 80
				80 80 80 80 80 80 80 80 80 80 80 80 80 80 80 80 80 80
				80 80 80 80 80 80 80 80 80 80 80 80 80 80 80 80 80 80
				80 80 80 80 80 80 80 80 80 80 80 80 80 80 80 80 80 80
				80 80 80 80 80 80 80 80 80 80 80 80 80 80 80 80 80 80
				80 80 80 80 80 80 80 80 80 80 80 80 80 80 80 80 80 80
				80 80 80 80 80 80 80 80 80 80 80 80 80 80 80 80 80 80
				80 80 80 80 80 80 80 80 80 80 80 80 80 80 80 80 80 80
				80 80 80 80 80 80 80 80 80 80 80 80 80 80 80 80 80 80
				80 80 80 80 80 80 80 80 80 80 80 80 80 80 80 80 80 80
				80 80 80 80 80 80 80 80 80 80 80 80 80 80 80 80 80 80
				80 80 80 80 80 80 80 80 80 80 80 80 80 80 80 80 80 80
				80 80 80 80 80 80 80 80 80 80 80 80 80 80 80 80 80 80
				80 80 80 80 80 80 80 80 80 80 80 80 80 80 80 80 80 80
				80 80 80 80 80 80 80 80 80 80 80 80 80 80 80 80 80 80
				80 80 80 80 80 80 80 80 80 80 80 80 80 80 80 80 80 80
				80 80 80 80 80 80 80 80 80 80 80 80 80 80 80 80 80 80
				80 80 80 80 80 80 80 80 80 80 80 80 80 80 80 80 80 80
				80 80 80 80 80 80 80 80 80 80 80 80 80 80 80 80 80 80
				80 80 80 80 80 80 80 80 80 80 80 80 80 80 80 80 80 80
				80 80 80 80 80 80 80 80 80 80 80 80 80 80 80 80 80 80
				80 80 80 80 80 80 80 80 80 80 80 80 80 80 80 80 80 80
				80 80 80 80 80 80 80 80 80 80 80 80 80 80 80 80 80 80
				>;

			PS_Config_Lmt_FW_CC_N = <
				(-80) (-80) (-80) (-80) (-80) (-80) (-80) (-80) (-80) (-80) (-80) (-80) (-80) (-80) (-80) (-80) (-80) (-80)
				(-80) (-80) (-80) (-80) (-80) (-80) (-80) (-80) (-80) (-80) (-80) (-80) (-80) (-80) (-80) (-80) (-80) (-80)
				(-80) (-80) (-80) (-80) (-80) (-80) (-80) (-80) (-80) (-80) (-80) (-80) (-80) (-80) (-80) (-80) (-80) (-80)
				(-80) (-80) (-80) (-80) (-80) (-80) (-80) (-80) (-80) (-80) (-80) (-80) (-80) (-80) (-80) (-80) (-80) (-80)
				(-80) (-80) (-80) (-80) (-80) (-80) (-80) (-80) (-80) (-80) (-80) (-80) (-80) (-80) (-80) (-80) (-80) (-80)
				(-80) (-80) (-80) (-80) (-80) (-80) (-80) (-80) (-80) (-80) (-80) (-80) (-80) (-80) (-80) (-80) (-80) (-80)
				(-80) (-80) (-80) (-80) (-80) (-80) (-80) (-80) (-80) (-80) (-80) (-80) (-80) (-80) (-80) (-80) (-80) (-80)
				(-80) (-80) (-80) (-80) (-80) (-80) (-80) (-80) (-80) (-80) (-80) (-80) (-80) (-80) (-80) (-80) (-80) (-80)
				(-80) (-80) (-80) (-80) (-80) (-80) (-80) (-80) (-80) (-80) (-80) (-80) (-80) (-80) (-80) (-80) (-80) (-80)
				(-80) (-80) (-80) (-80) (-80) (-80) (-80) (-80) (-80) (-80) (-80) (-80) (-80) (-80) (-80) (-80) (-80) (-80)
				(-80) (-80) (-80) (-80) (-80) (-80) (-80) (-80) (-80) (-80) (-80) (-80) (-80) (-80) (-80) (-80) (-80) (-80)
				(-80) (-80) (-80) (-80) (-80) (-80) (-80) (-80) (-80) (-80) (-80) (-80) (-80) (-80) (-80) (-80) (-80) (-80)
				(-80) (-80) (-80) (-80) (-80) (-80) (-80) (-80) (-80) (-80) (-80) (-80) (-80) (-80) (-80) (-80) (-80) (-80)
				(-80) (-80) (-80) (-80) (-80) (-80) (-80) (-80) (-80) (-80) (-80) (-80) (-80) (-80) (-80) (-80) (-80) (-80)
				(-80) (-80) (-80) (-80) (-80) (-80) (-80) (-80) (-80) (-80) (-80) (-80) (-80) (-80) (-80) (-80) (-80) (-80)
				(-80) (-80) (-80) (-80) (-80) (-80) (-80) (-80) (-80) (-80) (-80) (-80) (-80) (-80) (-80) (-80) (-80) (-80)
				(-80) (-80) (-80) (-80) (-80) (-80) (-80) (-80) (-80) (-80) (-80) (-80) (-80) (-80) (-80) (-80) (-80) (-80)
				(-80) (-80) (-80) (-80) (-80) (-80) (-80) (-80) (-80) (-80) (-80) (-80) (-80) (-80) (-80) (-80) (-80) (-80)
				(-80) (-80) (-80) (-80) (-80) (-80) (-80) (-80) (-80) (-80) (-80) (-80) (-80) (-80) (-80) (-80) (-80) (-80)
				(-80) (-80) (-80) (-80) (-80) (-80) (-80) (-80) (-80) (-80) (-80) (-80) (-80) (-80) (-80) (-80) (-80) (-80)
				(-80) (-80) (-80) (-80) (-80) (-80) (-80) (-80) (-80) (-80) (-80) (-80) (-80) (-80) (-80) (-80) (-80) (-80)
				(-80) (-80) (-80) (-80) (-80) (-80) (-80) (-80) (-80) (-80) (-80) (-80) (-80) (-80) (-80) (-80) (-80) (-80)
				(-80) (-80) (-80) (-80) (-80) (-80) (-80) (-80) (-80) (-80) (-80) (-80) (-80) (-80) (-80) (-80) (-80) (-80)
				(-80) (-80) (-80) (-80) (-80) (-80) (-80) (-80) (-80) (-80) (-80) (-80) (-80) (-80) (-80) (-80) (-80) (-80)
				(-80) (-80) (-80) (-80) (-80) (-80) (-80) (-80) (-80) (-80) (-80) (-80) (-80) (-80) (-80) (-80) (-80) (-80)
				(-80) (-80) (-80) (-80) (-80) (-80) (-80) (-80) (-80) (-80) (-80) (-80) (-80) (-80) (-80) (-80) (-80) (-80)
				(-80) (-80) (-80) (-80) (-80) (-80) (-80) (-80) (-80) (-80) (-80) (-80) (-80) (-80) (-80) (-80) (-80) (-80)
				(-80) (-80) (-80) (-80) (-80) (-80) (-80) (-80) (-80) (-80) (-80) (-80) (-80) (-80) (-80) (-80) (-80) (-80)
				(-80) (-80) (-80) (-80) (-80) (-80) (-80) (-80) (-80) (-80) (-80) (-80) (-80) (-80) (-80) (-80) (-80) (-80)
				(-80) (-80) (-80) (-80) (-80) (-80) (-80) (-80) (-80) (-80) (-80) (-80) (-80) (-80) (-80) (-80) (-80) (-80)
				(-80) (-80) (-80) (-80) (-80) (-80) (-80) (-80) (-80) (-80) (-80) (-80) (-80) (-80) (-80) (-80) (-80) (-80)
				(-80) (-80) (-80) (-80) (-80) (-80) (-80) (-80) (-80) (-80) (-80) (-80) (-80) (-80) (-80) (-80) (-80) (-80)
				(-80) (-80) (-80) (-80) (-80) (-80) (-80) (-80) (-80) (-80) (-80) (-80) (-80) (-80) (-80) (-80) (-80) (-80)
				(-80) (-80) (-80) (-80) (-80) (-80) (-80) (-80) (-80) (-80) (-80) (-80) (-80) (-80) (-80) (-80) (-80) (-80)
				(-80) (-80) (-80) (-80) (-80) (-80) (-80) (-80) (-80) (-80) (-80) (-80) (-80) (-80) (-80) (-80) (-80) (-80)
				(-80) (-80) (-80) (-80) (-80) (-80) (-80) (-80) (-80) (-80) (-80) (-80) (-80) (-80) (-80) (-80) (-80) (-80)
				(-80) (-80) (-80) (-80) (-80) (-80) (-80) (-80) (-80) (-80) (-80) (-80) (-80) (-80) (-80) (-80) (-80) (-80)
				(-80) (-80) (-80) (-80) (-80) (-80) (-80) (-80) (-80) (-80) (-80) (-80) (-80) (-80) (-80) (-80) (-80) (-80)
				(-80) (-80) (-80) (-80) (-80) (-80) (-80) (-80) (-80) (-80) (-80) (-80) (-80) (-80) (-80) (-80) (-80) (-80)
				>;

			PS_Config_Lmt_FW_Diff_P = <
				75 75 75 75 75 75 75 75 75 75 75 75 75 75 75 75 75 75
				75 75 75 75 75 75 75 75 75 75 75 75 75 75 75 75 75 75
				75 75 75 75 75 75 75 75 75 75 75 75 75 75 75 75 75 75
				75 75 75 75 75 75 75 75 75 75 75 75 75 75 75 75 75 75
				75 75 75 75 75 75 75 75 75 75 75 75 75 75 75 75 75 75
				75 75 75 75 75 75 75 75 75 75 75 75 75 75 75 75 75 75
				75 75 75 75 75 75 75 75 75 75 75 75 75 75 75 75 75 75
				75 75 75 75 75 75 75 75 75 75 75 75 75 75 75 75 75 75
				75 75 75 75 75 75 75 75 75 75 75 75 75 75 75 75 75 75
				75 75 75 75 75 75 75 75 75 75 75 75 75 75 75 75 75 75
				75 75 75 75 75 75 75 75 75 75 75 75 75 75 75 75 75 75
				75 75 75 75 75 75 75 75 75 75 75 75 75 75 75 75 75 75
				75 75 75 75 75 75 75 75 75 75 75 75 75 75 75 75 75 75
				75 75 75 75 75 75 75 75 75 75 75 75 75 75 75 75 75 75
				75 75 75 75 75 75 75 75 75 75 75 75 75 75 75 75 75 75
				75 75 75 75 75 75 75 75 75 75 75 75 75 75 75 75 75 75
				75 75 75 75 75 75 75 75 75 75 75 75 75 75 75 75 75 75
				75 75 75 75 75 75 75 75 75 75 75 75 75 75 75 75 75 75
				75 75 75 75 75 75 75 75 75 75 75 75 75 75 75 75 75 75
				75 75 75 75 75 75 75 75 75 75 75 75 75 75 75 75 75 75
				75 75 75 75 75 75 75 75 75 75 75 75 75 75 75 75 75 75
				75 75 75 75 75 75 75 75 75 75 75 75 75 75 75 75 75 75
				75 75 75 75 75 75 75 75 75 75 75 75 75 75 75 75 75 75
				75 75 75 75 75 75 75 75 75 75 75 75 75 75 75 75 75 75
				75 75 75 75 75 75 75 75 75 75 75 75 75 75 75 75 75 75
				75 75 75 75 75 75 75 75 75 75 75 75 75 75 75 75 75 75
				75 75 75 75 75 75 75 75 75 75 75 75 75 75 75 75 75 75
				75 75 75 75 75 75 75 75 75 75 75 75 75 75 75 75 75 75
				75 75 75 75 75 75 75 75 75 75 75 75 75 75 75 75 75 75
				75 75 75 75 75 75 75 75 75 75 75 75 75 75 75 75 75 75
				75 75 75 75 75 75 75 75 75 75 75 75 75 75 75 75 75 75
				75 75 75 75 75 75 75 75 75 75 75 75 75 75 75 75 75 75
				75 75 75 75 75 75 75 75 75 75 75 75 75 75 75 75 75 75
				75 75 75 75 75 75 75 75 75 75 75 75 75 75 75 75 75 75
				75 75 75 75 75 75 75 75 75 75 75 75 75 75 75 75 75 75
				75 75 75 75 75 75 75 75 75 75 75 75 75 75 75 75 75 75
				75 75 75 75 75 75 75 75 75 75 75 75 75 75 75 75 75 75
				75 75 75 75 75 75 75 75 75 75 75 75 75 75 75 75 75 75
				75 75 75 75 75 75 75 75 75 75 75 75 75 75 75 75 75 75
				>;

			PS_Config_Lmt_FW_Diff_N = <
				(-75) (-75) (-75) (-75) (-75) (-75) (-75) (-75) (-75) (-75) (-75) (-75) (-75) (-75) (-75) (-75) (-75) (-75)
				(-75) (-75) (-75) (-75) (-75) (-75) (-75) (-75) (-75) (-75) (-75) (-75) (-75) (-75) (-75) (-75) (-75) (-75)
				(-75) (-75) (-75) (-75) (-75) (-75) (-75) (-75) (-75) (-75) (-75) (-75) (-75) (-75) (-75) (-75) (-75) (-75)
				(-75) (-75) (-75) (-75) (-75) (-75) (-75) (-75) (-75) (-75) (-75) (-75) (-75) (-75) (-75) (-75) (-75) (-75)
				(-75) (-75) (-75) (-75) (-75) (-75) (-75) (-75) (-75) (-75) (-75) (-75) (-75) (-75) (-75) (-75) (-75) (-75)
				(-75) (-75) (-75) (-75) (-75) (-75) (-75) (-75) (-75) (-75) (-75) (-75) (-75) (-75) (-75) (-75) (-75) (-75)
				(-75) (-75) (-75) (-75) (-75) (-75) (-75) (-75) (-75) (-75) (-75) (-75) (-75) (-75) (-75) (-75) (-75) (-75)
				(-75) (-75) (-75) (-75) (-75) (-75) (-75) (-75) (-75) (-75) (-75) (-75) (-75) (-75) (-75) (-75) (-75) (-75)
				(-75) (-75) (-75) (-75) (-75) (-75) (-75) (-75) (-75) (-75) (-75) (-75) (-75) (-75) (-75) (-75) (-75) (-75)
				(-75) (-75) (-75) (-75) (-75) (-75) (-75) (-75) (-75) (-75) (-75) (-75) (-75) (-75) (-75) (-75) (-75) (-75)
				(-75) (-75) (-75) (-75) (-75) (-75) (-75) (-75) (-75) (-75) (-75) (-75) (-75) (-75) (-75) (-75) (-75) (-75)
				(-75) (-75) (-75) (-75) (-75) (-75) (-75) (-75) (-75) (-75) (-75) (-75) (-75) (-75) (-75) (-75) (-75) (-75)
				(-75) (-75) (-75) (-75) (-75) (-75) (-75) (-75) (-75) (-75) (-75) (-75) (-75) (-75) (-75) (-75) (-75) (-75)
				(-75) (-75) (-75) (-75) (-75) (-75) (-75) (-75) (-75) (-75) (-75) (-75) (-75) (-75) (-75) (-75) (-75) (-75)
				(-75) (-75) (-75) (-75) (-75) (-75) (-75) (-75) (-75) (-75) (-75) (-75) (-75) (-75) (-75) (-75) (-75) (-75)
				(-75) (-75) (-75) (-75) (-75) (-75) (-75) (-75) (-75) (-75) (-75) (-75) (-75) (-75) (-75) (-75) (-75) (-75)
				(-75) (-75) (-75) (-75) (-75) (-75) (-75) (-75) (-75) (-75) (-75) (-75) (-75) (-75) (-75) (-75) (-75) (-75)
				(-75) (-75) (-75) (-75) (-75) (-75) (-75) (-75) (-75) (-75) (-75) (-75) (-75) (-75) (-75) (-75) (-75) (-75)
				(-75) (-75) (-75) (-75) (-75) (-75) (-75) (-75) (-75) (-75) (-75) (-75) (-75) (-75) (-75) (-75) (-75) (-75)
				(-75) (-75) (-75) (-75) (-75) (-75) (-75) (-75) (-75) (-75) (-75) (-75) (-75) (-75) (-75) (-75) (-75) (-75)
				(-75) (-75) (-75) (-75) (-75) (-75) (-75) (-75) (-75) (-75) (-75) (-75) (-75) (-75) (-75) (-75) (-75) (-75)
				(-75) (-75) (-75) (-75) (-75) (-75) (-75) (-75) (-75) (-75) (-75) (-75) (-75) (-75) (-75) (-75) (-75) (-75)
				(-75) (-75) (-75) (-75) (-75) (-75) (-75) (-75) (-75) (-75) (-75) (-75) (-75) (-75) (-75) (-75) (-75) (-75)
				(-75) (-75) (-75) (-75) (-75) (-75) (-75) (-75) (-75) (-75) (-75) (-75) (-75) (-75) (-75) (-75) (-75) (-75)
				(-75) (-75) (-75) (-75) (-75) (-75) (-75) (-75) (-75) (-75) (-75) (-75) (-75) (-75) (-75) (-75) (-75) (-75)
				(-75) (-75) (-75) (-75) (-75) (-75) (-75) (-75) (-75) (-75) (-75) (-75) (-75) (-75) (-75) (-75) (-75) (-75)
				(-75) (-75) (-75) (-75) (-75) (-75) (-75) (-75) (-75) (-75) (-75) (-75) (-75) (-75) (-75) (-75) (-75) (-75)
				(-75) (-75) (-75) (-75) (-75) (-75) (-75) (-75) (-75) (-75) (-75) (-75) (-75) (-75) (-75) (-75) (-75) (-75)
				(-75) (-75) (-75) (-75) (-75) (-75) (-75) (-75) (-75) (-75) (-75) (-75) (-75) (-75) (-75) (-75) (-75) (-75)
				(-75) (-75) (-75) (-75) (-75) (-75) (-75) (-75) (-75) (-75) (-75) (-75) (-75) (-75) (-75) (-75) (-75) (-75)
				(-75) (-75) (-75) (-75) (-75) (-75) (-75) (-75) (-75) (-75) (-75) (-75) (-75) (-75) (-75) (-75) (-75) (-75)
				(-75) (-75) (-75) (-75) (-75) (-75) (-75) (-75) (-75) (-75) (-75) (-75) (-75) (-75) (-75) (-75) (-75) (-75)
				(-75) (-75) (-75) (-75) (-75) (-75) (-75) (-75) (-75) (-75) (-75) (-75) (-75) (-75) (-75) (-75) (-75) (-75)
				(-75) (-75) (-75) (-75) (-75) (-75) (-75) (-75) (-75) (-75) (-75) (-75) (-75) (-75) (-75) (-75) (-75) (-75)
				(-75) (-75) (-75) (-75) (-75) (-75) (-75) (-75) (-75) (-75) (-75) (-75) (-75) (-75) (-75) (-75) (-75) (-75)
				(-75) (-75) (-75) (-75) (-75) (-75) (-75) (-75) (-75) (-75) (-75) (-75) (-75) (-75) (-75) (-75) (-75) (-75)
				(-75) (-75) (-75) (-75) (-75) (-75) (-75) (-75) (-75) (-75) (-75) (-75) (-75) (-75) (-75) (-75) (-75) (-75)
				(-75) (-75) (-75) (-75) (-75) (-75) (-75) (-75) (-75) (-75) (-75) (-75) (-75) (-75) (-75) (-75) (-75) (-75)
				(-75) (-75) (-75) (-75) (-75) (-75) (-75) (-75) (-75) (-75) (-75) (-75) (-75) (-75) (-75) (-75) (-75) (-75)
				>;

			PS_Config_Lmt_FW_Digital_Diff_P = <
				75 75 75 75 75 75 75 75 75 75 75 75 75 75 75 75 75 75
				75 75 75 75 75 75 75 75 75 75 75 75 75 75 75 75 75 75
				75 75 75 75 75 75 75 75 75 75 75 75 75 75 75 75 75 75
				75 75 75 75 75 75 75 75 75 75 75 75 75 75 75 75 75 75
				75 75 75 75 75 75 75 75 75 75 75 75 75 75 75 75 75 75
				75 75 75 75 75 75 75 75 75 75 75 75 75 75 75 75 75 75
				75 75 75 75 75 75 75 75 75 75 75 75 75 75 75 75 75 75
				75 75 75 75 75 75 75 75 75 75 75 75 75 75 75 75 75 75
				75 75 75 75 75 75 75 75 75 75 75 75 75 75 75 75 75 75
				75 75 75 75 75 75 75 75 75 75 75 75 75 75 75 75 75 75
				75 75 75 75 75 75 75 75 75 75 75 75 75 75 75 75 75 75
				75 75 75 75 75 75 75 75 75 75 75 75 75 75 75 75 75 75
				75 75 75 75 75 75 75 75 75 75 75 75 75 75 75 75 75 75
				75 75 75 75 75 75 75 75 75 75 75 75 75 75 75 75 75 75
				75 75 75 75 75 75 75 75 75 75 75 75 75 75 75 75 75 75
				75 75 75 75 75 75 75 75 75 75 75 75 75 75 75 75 75 75
				75 75 75 75 75 75 75 75 75 75 75 75 75 75 75 75 75 75
				75 75 75 75 75 75 75 75 75 75 75 75 75 75 75 75 75 75
				75 75 75 75 75 75 75 75 75 75 75 75 75 75 75 75 75 75
				75 75 75 75 75 75 75 75 75 75 75 75 75 75 75 75 75 75
				75 75 75 75 75 75 75 75 75 75 75 75 75 75 75 75 75 75
				75 75 75 75 75 75 75 75 75 75 75 75 75 75 75 75 75 75
				75 75 75 75 75 75 75 75 75 75 75 75 75 75 75 75 75 75
				75 75 75 75 75 75 75 75 75 75 75 75 75 75 75 75 75 75
				75 75 75 75 75 75 75 75 75 75 75 75 75 75 75 75 75 75
				75 75 75 75 75 75 75 75 75 75 75 75 75 75 75 75 75 75
				75 75 75 75 75 75 75 75 75 75 75 75 75 75 75 75 75 75
				75 75 75 75 75 75 75 75 75 75 75 75 75 75 75 75 75 75
				75 75 75 75 75 75 75 75 75 75 75 75 75 75 75 75 75 75
				75 75 75 75 75 75 75 75 75 75 75 75 75 75 75 75 75 75
				75 75 75 75 75 75 75 75 75 75 75 75 75 75 75 75 75 75
				75 75 75 75 75 75 75 75 75 75 75 75 75 75 75 75 75 75
				75 75 75 75 75 75 75 75 75 75 75 75 75 75 75 75 75 75
				75 75 75 75 75 75 75 75 75 75 75 75 75 75 75 75 75 75
				75 75 75 75 75 75 75 75 75 75 75 75 75 75 75 75 75 75
				75 75 75 75 75 75 75 75 75 75 75 75 75 75 75 75 75 75
				75 75 75 75 75 75 75 75 75 75 75 75 75 75 75 75 75 75
				75 75 75 75 75 75 75 75 75 75 75 75 75 75 75 75 75 75
				75 75 75 75 75 75 75 75 75 75 75 75 75 75 75 75 75 75
				>;

			PS_Config_Lmt_FW_Digital_Diff_N = <
				(-75) (-75) (-75) (-75) (-75) (-75) (-75) (-75) (-75) (-75) (-75) (-75) (-75) (-75) (-75) (-75) (-75) (-75)
				(-75) (-75) (-75) (-75) (-75) (-75) (-75) (-75) (-75) (-75) (-75) (-75) (-75) (-75) (-75) (-75) (-75) (-75)
				(-75) (-75) (-75) (-75) (-75) (-75) (-75) (-75) (-75) (-75) (-75) (-75) (-75) (-75) (-75) (-75) (-75) (-75)
				(-75) (-75) (-75) (-75) (-75) (-75) (-75) (-75) (-75) (-75) (-75) (-75) (-75) (-75) (-75) (-75) (-75) (-75)
				(-75) (-75) (-75) (-75) (-75) (-75) (-75) (-75) (-75) (-75) (-75) (-75) (-75) (-75) (-75) (-75) (-75) (-75)
				(-75) (-75) (-75) (-75) (-75) (-75) (-75) (-75) (-75) (-75) (-75) (-75) (-75) (-75) (-75) (-75) (-75) (-75)
				(-75) (-75) (-75) (-75) (-75) (-75) (-75) (-75) (-75) (-75) (-75) (-75) (-75) (-75) (-75) (-75) (-75) (-75)
				(-75) (-75) (-75) (-75) (-75) (-75) (-75) (-75) (-75) (-75) (-75) (-75) (-75) (-75) (-75) (-75) (-75) (-75)
				(-75) (-75) (-75) (-75) (-75) (-75) (-75) (-75) (-75) (-75) (-75) (-75) (-75) (-75) (-75) (-75) (-75) (-75)
				(-75) (-75) (-75) (-75) (-75) (-75) (-75) (-75) (-75) (-75) (-75) (-75) (-75) (-75) (-75) (-75) (-75) (-75)
				(-75) (-75) (-75) (-75) (-75) (-75) (-75) (-75) (-75) (-75) (-75) (-75) (-75) (-75) (-75) (-75) (-75) (-75)
				(-75) (-75) (-75) (-75) (-75) (-75) (-75) (-75) (-75) (-75) (-75) (-75) (-75) (-75) (-75) (-75) (-75) (-75)
				(-75) (-75) (-75) (-75) (-75) (-75) (-75) (-75) (-75) (-75) (-75) (-75) (-75) (-75) (-75) (-75) (-75) (-75)
				(-75) (-75) (-75) (-75) (-75) (-75) (-75) (-75) (-75) (-75) (-75) (-75) (-75) (-75) (-75) (-75) (-75) (-75)
				(-75) (-75) (-75) (-75) (-75) (-75) (-75) (-75) (-75) (-75) (-75) (-75) (-75) (-75) (-75) (-75) (-75) (-75)
				(-75) (-75) (-75) (-75) (-75) (-75) (-75) (-75) (-75) (-75) (-75) (-75) (-75) (-75) (-75) (-75) (-75) (-75)
				(-75) (-75) (-75) (-75) (-75) (-75) (-75) (-75) (-75) (-75) (-75) (-75) (-75) (-75) (-75) (-75) (-75) (-75)
				(-75) (-75) (-75) (-75) (-75) (-75) (-75) (-75) (-75) (-75) (-75) (-75) (-75) (-75) (-75) (-75) (-75) (-75)
				(-75) (-75) (-75) (-75) (-75) (-75) (-75) (-75) (-75) (-75) (-75) (-75) (-75) (-75) (-75) (-75) (-75) (-75)
				(-75) (-75) (-75) (-75) (-75) (-75) (-75) (-75) (-75) (-75) (-75) (-75) (-75) (-75) (-75) (-75) (-75) (-75)
				(-75) (-75) (-75) (-75) (-75) (-75) (-75) (-75) (-75) (-75) (-75) (-75) (-75) (-75) (-75) (-75) (-75) (-75)
				(-75) (-75) (-75) (-75) (-75) (-75) (-75) (-75) (-75) (-75) (-75) (-75) (-75) (-75) (-75) (-75) (-75) (-75)
				(-75) (-75) (-75) (-75) (-75) (-75) (-75) (-75) (-75) (-75) (-75) (-75) (-75) (-75) (-75) (-75) (-75) (-75)
				(-75) (-75) (-75) (-75) (-75) (-75) (-75) (-75) (-75) (-75) (-75) (-75) (-75) (-75) (-75) (-75) (-75) (-75)
				(-75) (-75) (-75) (-75) (-75) (-75) (-75) (-75) (-75) (-75) (-75) (-75) (-75) (-75) (-75) (-75) (-75) (-75)
				(-75) (-75) (-75) (-75) (-75) (-75) (-75) (-75) (-75) (-75) (-75) (-75) (-75) (-75) (-75) (-75) (-75) (-75)
				(-75) (-75) (-75) (-75) (-75) (-75) (-75) (-75) (-75) (-75) (-75) (-75) (-75) (-75) (-75) (-75) (-75) (-75)
				(-75) (-75) (-75) (-75) (-75) (-75) (-75) (-75) (-75) (-75) (-75) (-75) (-75) (-75) (-75) (-75) (-75) (-75)
				(-75) (-75) (-75) (-75) (-75) (-75) (-75) (-75) (-75) (-75) (-75) (-75) (-75) (-75) (-75) (-75) (-75) (-75)
				(-75) (-75) (-75) (-75) (-75) (-75) (-75) (-75) (-75) (-75) (-75) (-75) (-75) (-75) (-75) (-75) (-75) (-75)
				(-75) (-75) (-75) (-75) (-75) (-75) (-75) (-75) (-75) (-75) (-75) (-75) (-75) (-75) (-75) (-75) (-75) (-75)
				(-75) (-75) (-75) (-75) (-75) (-75) (-75) (-75) (-75) (-75) (-75) (-75) (-75) (-75) (-75) (-75) (-75) (-75)
				(-75) (-75) (-75) (-75) (-75) (-75) (-75) (-75) (-75) (-75) (-75) (-75) (-75) (-75) (-75) (-75) (-75) (-75)
				(-75) (-75) (-75) (-75) (-75) (-75) (-75) (-75) (-75) (-75) (-75) (-75) (-75) (-75) (-75) (-75) (-75) (-75)
				(-75) (-75) (-75) (-75) (-75) (-75) (-75) (-75) (-75) (-75) (-75) (-75) (-75) (-75) (-75) (-75) (-75) (-75)
				(-75) (-75) (-75) (-75) (-75) (-75) (-75) (-75) (-75) (-75) (-75) (-75) (-75) (-75) (-75) (-75) (-75) (-75)
				(-75) (-75) (-75) (-75) (-75) (-75) (-75) (-75) (-75) (-75) (-75) (-75) (-75) (-75) (-75) (-75) (-75) (-75)
				(-75) (-75) (-75) (-75) (-75) (-75) (-75) (-75) (-75) (-75) (-75) (-75) (-75) (-75) (-75) (-75) (-75) (-75)
				(-75) (-75) (-75) (-75) (-75) (-75) (-75) (-75) (-75) (-75) (-75) (-75) (-75) (-75) (-75) (-75) (-75) (-75)
				>;

			PS_Config_Diff_Test_Frame = <50>;
			PS_Config_Digital_Diff_Test_Frame = <50>;
		};
	};
};
/*touch end*/

&pmxr2230_gpios {
    flash_therm_gpio7 {
        flash_therm_gpio7_default: flash_therm_gpio7_default {
            pins = "gpio7";
            bias-high-impedance;
        };
    };
};

&pm7550ba_gpios {
    charger_therm_gpio6 {
        charger_therm_gpio6_default: charger_therm_gpio6_default {
            pins = "gpio6";
            bias-high-impedance;
        };
    };
    wifi_therm_gpio3 {
        wifi_therm_gpio3_default: wifi_therm_gpio3_default {
            pins = "gpio3";
            bias-high-impedance;
        };
    };
    conn_therm2_gpio2 {
        conn_therm2_gpio2_default: conn_therm2_gpio2_default {
            pins = "gpio2";
            bias-high-impedance;
        };
    };
    therm_gpio4 {
        therm_gpio4_default: therm_gpio4_default {
            pins = "gpio4";
            bias-high-impedance;
        };
    };
};

&pmk8550_vadc {
    pinctrl-names = "default";
    pinctrl-0 = <&charger_therm_gpio6_default &wifi_therm_gpio3_default &conn_therm2_gpio2_default &flash_therm_gpio7_default &therm_gpio4_default>;

    pm7550ba_conn_therm {
            reg = <PM7550BA_ADC5_GEN3_AMUX_THM4_USB_THERM_100K_PU>;
            label = "pm7550ba_conn_therm";
            qcom,ratiometric;
            qcom,hw-settle-time = <200>;
            qcom,pre-scaling = <1 1>;
            qcom,adc-tm-type = <1>;
    };

    pm7550ba_charger_therm {
        reg = <PM7550BA_ADC5_GEN3_AMUX_THM6_GPIO6_100K_PU>;
        label = "pm7550ba_charger_therm";
        qcom,ratiometric;
        qcom,hw-settle-time = <200>;
        qcom,pre-scaling = <1 1>;
        qcom,adc-tm-type = <1>;
    };

    pm7550ba_wifi_therm {
        reg = <PM7550BA_ADC5_GEN3_AMUX3_GPIO3_100K_PU>;
        label = "pm7550ba_wifi_therm";
        qcom,ratiometric;
        qcom,hw-settle-time = <200>;
        qcom,pre-scaling = <1 1>;
        qcom,adc-tm-type = <1>;
    };

    pm7550ba_conn_therm2 {
        reg = <PM7550BA_ADC5_GEN3_AMUX2_GPIO2_100K_PU>;
        label = "pm7550ba_conn_therm2";
        qcom,ratiometric;
        qcom,hw-settle-time = <200>;
        qcom,pre-scaling = <1 1>;
        qcom,adc-tm-type = <1>;
    };
    pm7550ba_gpio_4_therm {
        reg = <PM7550BA_ADC5_GEN3_AMUX4_GPIO4_100K_PU>;
        label = "pm7550ba_gpio_4_therm";
        qcom,adc-tm-type = <0>;
        qcom,absolute;
        qcom,hw-settle-time = <200>;
        qcom,pre-scaling = <1 1>;
    };

    pmxr2230_pa_therm0 {
        reg = <PMXR2230_ADC5_GEN3_AMUX_THM1_100K_PU>;
        label = "pmxr2230_pa_therm0";
        qcom,ratiometric;
        qcom,hw-settle-time = <200>;
        qcom,pre-scaling = <1 1>;
        qcom,adc-tm-type = <1>;
    };

    pmxr2230_cpu_therm {
        reg = <PMXR2230_ADC5_GEN3_AMUX_THM2_100K_PU>;
        label = "pmxr2230_cpu_therm";
        qcom,ratiometric;
        qcom,hw-settle-time = <200>;
        qcom,pre-scaling = <1 1>;
        qcom,adc-tm-type = <1>;
    };

    pmxr2230_pa_therm1 {
        reg = <PMXR2230_ADC5_GEN3_AMUX_THM3_100K_PU>;
        label = "pmxr2230_pa_therm1";
        qcom,ratiometric;
        qcom,hw-settle-time = <200>;
        qcom,pre-scaling = <1 1>;
        qcom,adc-tm-type = <1>;
    };

    pmxr2230_quiet_therm {
        reg = <PMXR2230_ADC5_GEN3_AMUX_THM4_100K_PU>;
        label = "pmxr2230_quiet_therm";
        qcom,ratiometric;
        qcom,hw-settle-time = <200>;
        qcom,pre-scaling = <1 1>;
        qcom,adc-tm-type = <1>;
    };

    pmxr2230_gnss_therm {
        reg = <PMXR2230_ADC5_GEN3_AMUX_THM5_100K_PU>;
        label = "pmxr2230_gnss_therm";
        qcom,ratiometric;
        qcom,hw-settle-time = <200>;
        qcom,pre-scaling = <1 1>;
        qcom,adc-tm-type = <1>;
    };

    pmxr2230_flash_therm {
        reg = <PMXR2230_ADC5_GEN3_AMUX3_GPIO7_100K_PU>;
        label = "pmxr2230_flash_therm";
        qcom,ratiometric;
        qcom,hw-settle-time = <200>;
        qcom,pre-scaling = <1 1>;
        qcom,adc-tm-type = <1>;
    };
};

&thermal_zones {
    pa_therm0 {
        polling-delay-passive = <0>;
        polling-delay = <0>;
        thermal-sensors = <&pmk8550_vadc PMXR2230_ADC5_GEN3_AMUX_THM1_100K_PU>;
        trips {
            active-config0 {
                temperature = <125000>;
                hysteresis = <1000>;
                type = "passive";
            };
            active-config1 {
                temperature = <125000>;
                hysteresis = <1000>;
                type = "passive";
            };
        };
    };

    cpu_therm {
        polling-delay-passive = <0>;
        polling-delay = <0>;
        thermal-sensors = <&pmk8550_vadc PMXR2230_ADC5_GEN3_AMUX_THM2_100K_PU>;
        trips {
            active-config0 {
                temperature = <125000>;
                hysteresis = <1000>;
                type = "passive";
            };
            active-config1 {
                temperature = <125000>;
                hysteresis = <1000>;
                type = "passive";
            };
        };
    };

    pa_therm1 {
        polling-delay-passive = <0>;
        polling-delay = <0>;
        thermal-sensors = <&pmk8550_vadc PMXR2230_ADC5_GEN3_AMUX_THM3_100K_PU>;
        trips {
            active-config0 {
                temperature = <125000>;
                hysteresis = <1000>;
                type = "passive";
            };
            active-config1 {
                temperature = <125000>;
                hysteresis = <1000>;
                type = "passive";
            };
        };
    };

    quiet_therm {
        polling-delay-passive = <0>;
        polling-delay = <0>;
        thermal-sensors = <&pmk8550_vadc PMXR2230_ADC5_GEN3_AMUX_THM4_100K_PU>;
        trips {
            active-config0 {
                temperature = <125000>;
                hysteresis = <1000>;
                type = "passive";
            };
            active-config1 {
                temperature = <125000>;
                hysteresis = <1000>;
                type = "passive";
            };
        };
    };

    gnss_therm {
        polling-delay-passive = <0>;
        polling-delay = <0>;
        thermal-sensors = <&pmk8550_vadc PMXR2230_ADC5_GEN3_AMUX_THM5_100K_PU>;
        trips {
            active-config0 {
                temperature = <125000>;
                hysteresis = <1000>;
                type = "passive";
            };
            active-config1 {
                temperature = <125000>;
                hysteresis = <1000>;
                type = "passive";
            };
        };
    };

    flash_therm {
        polling-delay-passive = <0>;
        polling-delay = <0>;
        thermal-sensors = <&pmk8550_vadc PMXR2230_ADC5_GEN3_AMUX3_GPIO7_100K_PU>;
        trips {
            active-config0 {
                temperature = <125000>;
                hysteresis = <1000>;
                type = "passive";
            };
            active-config1 {
                temperature = <125000>;
                hysteresis = <1000>;
                type = "passive";
            };
        };
    };

    conn_therm {
        polling-delay-passive = <0>;
        polling-delay = <0>;
        thermal-sensors = <&pmk8550_vadc PM7550BA_ADC5_GEN3_AMUX_THM4_USB_THERM_100K_PU>;
        trips {
            active-config0 {
                temperature = <125000>;
                hysteresis = <1000>;
                type = "passive";
            };
            active-config1 {
                temperature = <125000>;
                hysteresis = <1000>;
                type = "passive";
            };
        };
    };

    charger_therm0 {
        polling-delay-passive = <0>;
        polling-delay = <0>;
        thermal-sensors = <&pmk8550_vadc PM7550BA_ADC5_GEN3_AMUX_THM6_GPIO6_100K_PU>;
        trips {
            active-config0 {
                temperature = <125000>;
                hysteresis = <1000>;
                type = "passive";
            };
            active-config1 {
                temperature = <125000>;
                hysteresis = <1000>;
                type = "passive";
            };
        };
    };

    wifi_therm {
        polling-delay-passive = <0>;
        polling-delay = <0>;
        thermal-sensors = <&pmk8550_vadc PM7550BA_ADC5_GEN3_AMUX3_GPIO3_100K_PU>;
        trips {
            active-config0 {
                temperature = <125000>;
                hysteresis = <1000>;
                type = "passive";
            };
            active-config1 {
                temperature = <125000>;
                hysteresis = <1000>;
                type = "passive";
            };
        };
    };

    conn_therm2 {
        polling-delay-passive = <0>;
        polling-delay = <0>;
        thermal-sensors = <&pmk8550_vadc PM7550BA_ADC5_GEN3_AMUX2_GPIO2_100K_PU>;
        trips {
            active-config0 {
                temperature = <125000>;
                hysteresis = <1000>;
                type = "passive";
            };
            active-config1 {
                temperature = <125000>;
                hysteresis = <1000>;
                type = "passive";
            };
        };
    };
};

/* NFC start:  tms + nxp*/
&qupv3_se1_i2c {
	status = "ok";
 	#address-cells = <1>;
	#size-cells = <0>;
	nfc@28 {
		clock-frequency = <400000>;
		status = "ok";
		compatible = "tms,nfc";
		reg = <0x28>;
		tms,device-name   = "tms_nfc";
		tms,device-count  = <1>;
		tms,irq-gpio      = <&tlmm 31 0x00>;
		tms,ven-gpio      = <&tlmm 7 0x00>;
		tms,download-gpio = <&tlmm 81 0x00>;
		tms,clkreq-gpio   = <&tlmm 6 0x00>;

		nxp,sn-ven-rstn   = <&tlmm 7 0x00>;
		nxp,sn-clkreq     = <&tlmm 6 0x00>;
		nxp,sn-irq        = <&tlmm 31 0x00>;
	};
};
/* NFC end */

/* USB start */
&pm7550ba_eusb2_repeater {
	qcom,param-override-seq =
		<0x00 0x50
		0x09 0x51
		0x01 0x52
		0x07 0x53
		0x01 0x54
		0x02 0x55
		0x00 0x56
		0x05 0x57
		0x02 0x58
		0x03 0x59
		0x01 0x5a
		0x02 0x5b>;
	qcom,param-override-seq-host-ms =
		<0x00 0x50
		0x0e 0x51
		0x01 0x52
		0x07 0x53
		0x01 0x54
		0x00 0x55
		0x00 0x56
		0x00 0x57
		0x02 0x58
		0x03 0x59
		0x01 0x5a
		0x02 0x5b>;
	qcom,param-override-seq-host =
		<0x00 0x50
		0x0e 0x51
		0x01 0x52
		0x07 0x53
		0x01 0x54
		0x03 0x55
		0x00 0x56
		0x07 0x57
		0x02 0x58
		0x03 0x59
		0x01 0x5a
		0x02 0x5b>;
};
/* USB end */

&usb0 {
    dwc3@a600000 {
        usb-phy = <&eusb2_phy0>, <&usb_nop_phy>;
        maximum-speed = "high-speed";
    };
};

&usb_qmp_dp_phy {
    status="disabled";
};

&battery_charger {
	qcom,shutdown-voltage = <2950>;
	mi,support-shutdown-delay;
	mi,support-ut-test;
	mi,support-ut-test-region;
	mi,support-ut-test-multi-volt;

	mi,cycle_volt_gl_nvt = "0,100,4130,4230,4400,4500,4580,100,300,4100,4200,4400,4500,4560,300,800,4100,4200,4400,4500,4550,800,10000,4100,4200,4400,4500,4530,";
	mi,cycle_volt_gl_sunwoda = "0,100,4050,4150,4400,4500,4580,100,300,4020,4120,4400,4500,4560,300,800,4020,4120,4400,4500,4550,800,10000,4020,4120,4400,4500,4530,";
	mi,cycle_step_curr_gl = "0,50,17600,12400,10991,9159,7327,50,100,17600,11780,10441,8701,6961,100,150,17600,11160,9892,8243,6954,150,300,17600,10540,9342,7785,6228,300,10000,17600,9920,8793,7327,5862,";
	mi,temp_term_curr_gl_nvt = "23,35,1950,35,40,3020,40,48,4592,";
	mi,temp_term_curr_gl_sunwoda = "23,35,3053,35,40,4213,40,48,5800,";
	mi,thermal_gl = "17600,15000,12000,9000,8000,7000,6000,5000,4000,3500,3000,2400,2000,1600,1000,500";

	mi,cycle_volt_cn_nvt = "0,100,4200,4300,4400,4500,4580,100,300,4170,4270,4400,4500,4560,300,800,4170,4270,4400,4500,4550,800,10000,4170,4270,4400,4500,4530,";
	mi,cycle_volt_cn_sunwoda = "0,100,4130,4230,4400,4500,4580,100,300,4100,4200,4400,4500,4560,300,800,4100,4200,4400,4500,4550,800,10000,4100,4200,4400,4500,4530,";
	mi,cycle_step_curr_cn = "0,50,15600,12400,11900,9917,7933,50,100,15600,11780,11305,9421,7537,100,150,15600,11160,10710,8925,7140,150,300,15600,10540,10115,8429,6743,300,10000,15600,9920,9520,7933,6347,";
	mi,temp_term_curr_cn_nvt = "23,35,1499,35,40,2180,40,48,2930,";
	mi,temp_term_curr_cn_sunwoda = "23,35,1785,35,40,2512,40,48,3305,";
	mi,thermal_cn = "15600,13500,11000,9000,8000,7000,6000,5000,4000,3500,3000,2500,2000,1500,1000,500";
};

&charger_partition
{
	status = "ok";
};
